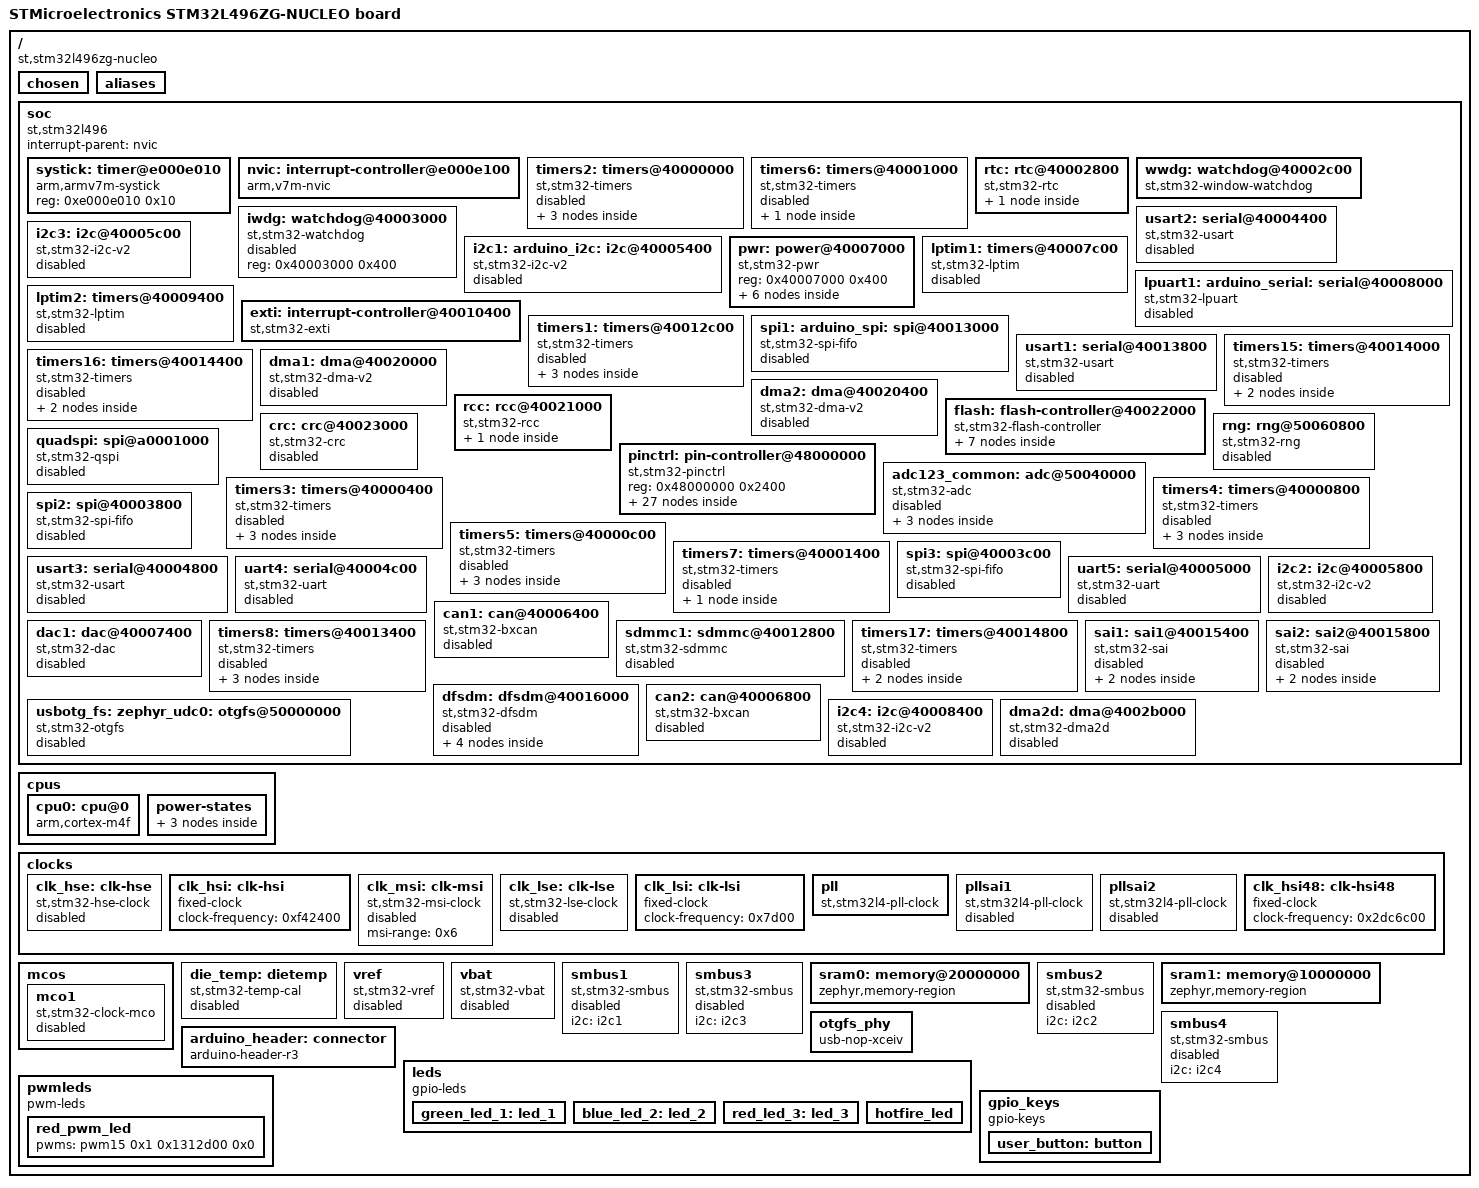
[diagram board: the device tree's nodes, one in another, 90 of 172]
/dts-v1/;

/* node '/' defined in zephyr/dts/common/skeleton.dtsi:9 */
/ {
	#address-cells = < 0x1 >;                              /* in zephyr/dts/common/skeleton.dtsi:10 */
	#size-cells = < 0x1 >;                                 /* in zephyr/dts/common/skeleton.dtsi:11 */
	compatible = "st,stm32l496zg-nucleo";                  /* in zephyr/boards/st/nucleo_l496zg/nucleo_l496zg.dts:14 */
	model = "STMicroelectronics STM32L496ZG-NUCLEO board"; /* in zephyr/boards/st/nucleo_l496zg/nucleo_l496zg.dts:15 */

	/* node '/chosen' defined in zephyr/dts/common/skeleton.dtsi:13 */
	chosen {
		zephyr,crc = &crc;                /* in zephyr/dts/arm/st/l4/stm32l4.dtsi:25 */
		zephyr,entropy = &rng;            /* in zephyr/dts/arm/st/l4/stm32l4.dtsi:26 */
		zephyr,flash-controller = &flash; /* in zephyr/dts/arm/st/l4/stm32l4.dtsi:27 */
		zephyr,console = &lpuart1;        /* in zephyr/boards/st/nucleo_l496zg/nucleo_l496zg.dts:18 */
		zephyr,shell-uart = &lpuart1;     /* in zephyr/boards/st/nucleo_l496zg/nucleo_l496zg.dts:19 */
		zephyr,sram = &sram0;             /* in zephyr/boards/st/nucleo_l496zg/nucleo_l496zg.dts:20 */
		zephyr,flash = &flash0;           /* in zephyr/boards/st/nucleo_l496zg/nucleo_l496zg.dts:21 */
	};

	/* node '/aliases' defined in zephyr/dts/common/skeleton.dtsi:15 */
	aliases {
		led1 = &blue_led_2;      /* in zephyr/boards/st/nucleo_l496zg/nucleo_l496zg.dts:63 */
		led2 = &red_led_3;       /* in zephyr/boards/st/nucleo_l496zg/nucleo_l496zg.dts:64 */
		pwm-led0 = &red_pwm_led; /* in zephyr/boards/st/nucleo_l496zg/nucleo_l496zg.dts:65 */
		sw0 = &user_button;      /* in zephyr/boards/st/nucleo_l496zg/nucleo_l496zg.dts:66 */
		watchdog0 = &wwdg;       /* in zephyr/boards/st/nucleo_l496zg/nucleo_l496zg.dts:67 */
		led0 = &hotfire_led;     /* in ../projects/grp/daq-module/firmware/app.overlay:13 */
	};

	/* node '/soc' defined in zephyr/dts/arm/armv7-m.dtsi:6 */
	soc {
		ranges;                       /* in zephyr/dts/arm/armv7-m.dtsi:8 */
		#address-cells = < 0x1 >;     /* in zephyr/dts/arm/armv7-m.dtsi:9 */
		#size-cells = < 0x1 >;        /* in zephyr/dts/arm/armv7-m.dtsi:10 */
		interrupt-parent = < &nvic >; /* in zephyr/dts/arm/armv7-m.dtsi:11 */
		compatible = "st,stm32l496",
		             "st,stm32l4",
		             "simple-bus";    /* in zephyr/dts/arm/st/l4/stm32l496.dtsi:20 */

		/* node '/soc/timer@e000e010' defined in zephyr/dts/arm/armv7-m.dtsi:13 */
		systick: timer@e000e010 {
			compatible = "arm,armv7m-systick"; /* in zephyr/dts/arm/armv7-m.dtsi:14 */
			reg = < 0xe000e010 0x10 >;         /* in zephyr/dts/arm/armv7-m.dtsi:15 */
		};

		/* node '/soc/interrupt-controller@e000e100' defined in zephyr/dts/arm/armv7-m.dtsi:18 */
		nvic: interrupt-controller@e000e100 {
			compatible = "arm,v7m-nvic";         /* in zephyr/dts/arm/armv7-m.dtsi:19 */
			reg = < 0xe000e100 0xc00 >;          /* in zephyr/dts/arm/armv7-m.dtsi:20 */
			#address-cells = < 0x1 >;            /* in zephyr/dts/arm/armv7-m.dtsi:21 */
			interrupt-controller;                /* in zephyr/dts/arm/armv7-m.dtsi:22 */
			#interrupt-cells = < 0x2 >;          /* in zephyr/dts/arm/armv7-m.dtsi:23 */
			arm,num-irq-priority-bits = < 0x4 >; /* in zephyr/dts/arm/st/l4/stm32l4.dtsi:647 */
			phandle = < 0x1 >;                   /* in zephyr/dts/arm/armv7-m.dtsi:11 */
		};

		/* node '/soc/timers@40000000' defined in zephyr/dts/arm/st/l4/stm32l4.dtsi:123 */
		timers2: timers@40000000 {
			compatible = "st,stm32-timers"; /* in zephyr/dts/arm/st/l4/stm32l4.dtsi:124 */
			reg = < 0x40000000 0x400 >;     /* in zephyr/dts/arm/st/l4/stm32l4.dtsi:125 */
			clocks = < &rcc 0x58 0x1 >,
			         < &rcc 0x9 0xff >;     /* in zephyr/dts/arm/st/l4/stm32l4.dtsi:126 */
			resets = < &rctl 0x700 >;       /* in zephyr/dts/arm/st/l4/stm32l4.dtsi:128 */
			interrupts = < 0x1c 0x0 >;      /* in zephyr/dts/arm/st/l4/stm32l4.dtsi:129 */
			interrupt-names = "global";     /* in zephyr/dts/arm/st/l4/stm32l4.dtsi:130 */
			st,prescaler = < 0x0 >;         /* in zephyr/dts/arm/st/l4/stm32l4.dtsi:131 */
			status = "disabled";            /* in ../projects/grp/daq-module/firmware/app.overlay:30 */

			/* node '/soc/timers@40000000/pwm' defined in zephyr/dts/arm/st/l4/stm32l4.dtsi:134 */
			pwm2: pwm {
				compatible = "st,stm32-pwm";   /* in zephyr/dts/arm/st/l4/stm32l4.dtsi:135 */
				#pwm-cells = < 0x3 >;          /* in zephyr/dts/arm/st/l4/stm32l4.dtsi:136 */
				pinctrl-0 = < &tim2_ch1_pa0 >; /* in zephyr/boards/st/nucleo_l496zg/nucleo_l496zg.dts:145 */
				pinctrl-names = "default";     /* in zephyr/boards/st/nucleo_l496zg/nucleo_l496zg.dts:146 */
				status = "okay";               /* in zephyr/boards/st/nucleo_l496zg/nucleo_l496zg.dts:147 */
			};

			/* node '/soc/timers@40000000/counter' defined in zephyr/dts/arm/st/l4/stm32l4.dtsi:140 */
			counter {
				compatible = "st,stm32-counter"; /* in zephyr/dts/arm/st/l4/stm32l4.dtsi:141 */
				status = "disabled";             /* in zephyr/dts/arm/st/l4/stm32l4.dtsi:142 */
			};

			/* node '/soc/timers@40000000/qdec' defined in zephyr/dts/arm/st/l4/stm32l4.dtsi:145 */
			qdec {
				compatible = "st,stm32-qdec";    /* in zephyr/dts/arm/st/l4/stm32l4.dtsi:146 */
				st,input-filter-level = < 0x0 >; /* in zephyr/dts/arm/st/l4/stm32l4.dtsi:147 */
				status = "disabled";             /* in zephyr/dts/arm/st/l4/stm32l4.dtsi:148 */
			};
		};

		/* node '/soc/timers@40001000' defined in zephyr/dts/arm/st/l4/stm32l4.dtsi:152 */
		timers6: timers@40001000 {
			compatible = "st,stm32-timers"; /* in zephyr/dts/arm/st/l4/stm32l4.dtsi:153 */
			reg = < 0x40001000 0x400 >;     /* in zephyr/dts/arm/st/l4/stm32l4.dtsi:154 */
			clocks = < &rcc 0x58 0x10 >,
			         < &rcc 0x9 0xff >;     /* in zephyr/dts/arm/st/l4/stm32l4.dtsi:155 */
			resets = < &rctl 0x704 >;       /* in zephyr/dts/arm/st/l4/stm32l4.dtsi:157 */
			interrupts = < 0x36 0x0 >;      /* in zephyr/dts/arm/st/l4/stm32l4.dtsi:158 */
			interrupt-names = "global";     /* in zephyr/dts/arm/st/l4/stm32l4.dtsi:159 */
			st,prescaler = < 0x0 >;         /* in zephyr/dts/arm/st/l4/stm32l4.dtsi:160 */
			status = "disabled";            /* in zephyr/dts/arm/st/l4/stm32l4.dtsi:161 */

			/* node '/soc/timers@40001000/counter' defined in zephyr/dts/arm/st/l4/stm32l4.dtsi:163 */
			counter {
				compatible = "st,stm32-counter"; /* in zephyr/dts/arm/st/l4/stm32l4.dtsi:164 */
				status = "disabled";             /* in zephyr/dts/arm/st/l4/stm32l4.dtsi:165 */
			};
		};

		/* node '/soc/rtc@40002800' defined in zephyr/dts/arm/st/l4/stm32l4.dtsi:169 */
		rtc: rtc@40002800 {
			compatible = "st,stm32-rtc";       /* in zephyr/dts/arm/st/l4/stm32l4.dtsi:170 */
			reg = < 0x40002800 0x400 >;        /* in zephyr/dts/arm/st/l4/stm32l4.dtsi:171 */
			interrupts = < 0x29 0x0 >;         /* in zephyr/dts/arm/st/l4/stm32l4.dtsi:172 */
			prescaler = < 0x8000 >;            /* in zephyr/dts/arm/st/l4/stm32l4.dtsi:174 */
			alarms-count = < 0x2 >;            /* in zephyr/dts/arm/st/l4/stm32l4.dtsi:175 */
			alrm-exti-line = < 0x12 >;         /* in zephyr/dts/arm/st/l4/stm32l4.dtsi:176 */
			clocks = < &rcc 0x58 0x10000000 >,
			         < &rcc 0x3 0x2280090 >;   /* in zephyr/boards/st/nucleo_l496zg/nucleo_l496zg.dts:179 */
			status = "okay";                   /* in zephyr/boards/st/nucleo_l496zg/nucleo_l496zg.dts:181 */

			/* node '/soc/rtc@40002800/backup_regs' defined in zephyr/dts/arm/st/l4/stm32l471.dtsi:126 */
			bbram: backup_regs {
				compatible = "st,stm32-bbram"; /* in zephyr/dts/arm/st/l4/stm32l471.dtsi:127 */
				st,backup-regs = < 0x20 >;     /* in zephyr/dts/arm/st/l4/stm32l471.dtsi:128 */
				status = "disabled";           /* in zephyr/dts/arm/st/l4/stm32l471.dtsi:129 */
			};
		};

		/* node '/soc/watchdog@40002c00' defined in zephyr/dts/arm/st/l4/stm32l4.dtsi:180 */
		wwdg: watchdog@40002c00 {
			compatible = "st,stm32-window-watchdog"; /* in zephyr/dts/arm/st/l4/stm32l4.dtsi:181 */
			reg = < 0x40002c00 0x400 >;              /* in zephyr/dts/arm/st/l4/stm32l4.dtsi:182 */
			clocks = < &rcc 0x58 0x800 >;            /* in zephyr/dts/arm/st/l4/stm32l4.dtsi:183 */
			interrupts = < 0x0 0x0 >;                /* in zephyr/dts/arm/st/l4/stm32l4.dtsi:184 */
			status = "okay";                         /* in zephyr/boards/st/nucleo_l496zg/nucleo_l496zg.dts:185 */
		};

		/* node '/soc/watchdog@40003000' defined in zephyr/dts/arm/st/l4/stm32l4.dtsi:188 */
		iwdg: watchdog@40003000 {
			compatible = "st,stm32-watchdog"; /* in zephyr/dts/arm/st/l4/stm32l4.dtsi:189 */
			reg = < 0x40003000 0x400 >;       /* in zephyr/dts/arm/st/l4/stm32l4.dtsi:190 */
			status = "disabled";              /* in zephyr/dts/arm/st/l4/stm32l4.dtsi:191 */
		};

		/* node '/soc/serial@40004400' defined in zephyr/dts/arm/st/l4/stm32l4.dtsi:194 */
		usart2: serial@40004400 {
			compatible = "st,stm32-usart",
			             "st,stm32-uart";                  /* in zephyr/dts/arm/st/l4/stm32l4.dtsi:195 */
			reg = < 0x40004400 0x400 >;                    /* in zephyr/dts/arm/st/l4/stm32l4.dtsi:196 */
			clocks = < &rcc 0x58 0x20000 >;                /* in zephyr/dts/arm/st/l4/stm32l4.dtsi:197 */
			resets = < &rctl 0x711 >;                      /* in zephyr/dts/arm/st/l4/stm32l4.dtsi:198 */
			interrupts = < 0x26 0x0 >;                     /* in zephyr/dts/arm/st/l4/stm32l4.dtsi:199 */
			pinctrl-0 = < &usart2_tx_pd5 &usart2_rx_pd6 >; /* in zephyr/boards/st/nucleo_l496zg/nucleo_l496zg.dts:102 */
			pinctrl-names = "default";                     /* in zephyr/boards/st/nucleo_l496zg/nucleo_l496zg.dts:103 */
			current-speed = < 0x1c200 >;                   /* in zephyr/boards/st/nucleo_l496zg/nucleo_l496zg.dts:104 */
			status = "disabled";                           /* in ../projects/grp/daq-module/firmware/app.overlay:24 */
		};

		/* node '/soc/i2c@40005400' defined in zephyr/dts/arm/st/l4/stm32l4.dtsi:203 */
		i2c1: arduino_i2c: i2c@40005400 {
			compatible = "st,stm32-i2c-v2";              /* in zephyr/dts/arm/st/l4/stm32l4.dtsi:204 */
			reg = < 0x40005400 0x400 >;                  /* in zephyr/dts/arm/st/l4/stm32l4.dtsi:205 */
			#address-cells = < 0x1 >;                    /* in zephyr/dts/arm/st/l4/stm32l4.dtsi:207 */
			#size-cells = < 0x0 >;                       /* in zephyr/dts/arm/st/l4/stm32l4.dtsi:208 */
			clocks = < &rcc 0x58 0x200000 >;             /* in zephyr/dts/arm/st/l4/stm32l4.dtsi:209 */
			interrupts = < 0x1f 0x0 >,
			             < 0x20 0x0 >;                   /* in zephyr/dts/arm/st/l4/stm32l4.dtsi:210 */
			interrupt-names = "event",
			                  "error";                   /* in zephyr/dts/arm/st/l4/stm32l4.dtsi:211 */
			pinctrl-0 = < &i2c1_scl_pb8 &i2c1_sda_pb9 >; /* in zephyr/boards/st/nucleo_l496zg/nucleo_l496zg.dts:163 */
			pinctrl-names = "default";                   /* in zephyr/boards/st/nucleo_l496zg/nucleo_l496zg.dts:164 */
			scl-gpios = < &gpiob 0x8 0x0 >;              /* in zephyr/boards/st/nucleo_l496zg/nucleo_l496zg.dts:165 */
			sda-gpios = < &gpiob 0x9 0x0 >;              /* in zephyr/boards/st/nucleo_l496zg/nucleo_l496zg.dts:166 */
			clock-frequency = < 0x61a80 >;               /* in zephyr/boards/st/nucleo_l496zg/nucleo_l496zg.dts:167 */
			status = "disabled";                         /* in ../projects/grp/daq-module/firmware/app.overlay:28 */
			phandle = < 0x23 >;                          /* in zephyr/dts/arm/st/l4/stm32l4.dtsi:628 */
		};

		/* node '/soc/i2c@40005c00' defined in zephyr/dts/arm/st/l4/stm32l4.dtsi:215 */
		i2c3: i2c@40005c00 {
			compatible = "st,stm32-i2c-v2";  /* in zephyr/dts/arm/st/l4/stm32l4.dtsi:216 */
			reg = < 0x40005c00 0x400 >;      /* in zephyr/dts/arm/st/l4/stm32l4.dtsi:217 */
			clock-frequency = < 0x186a0 >;   /* in zephyr/dts/arm/st/l4/stm32l4.dtsi:218 */
			#address-cells = < 0x1 >;        /* in zephyr/dts/arm/st/l4/stm32l4.dtsi:219 */
			#size-cells = < 0x0 >;           /* in zephyr/dts/arm/st/l4/stm32l4.dtsi:220 */
			clocks = < &rcc 0x58 0x800000 >; /* in zephyr/dts/arm/st/l4/stm32l4.dtsi:221 */
			interrupts = < 0x48 0x0 >,
			             < 0x49 0x0 >;       /* in zephyr/dts/arm/st/l4/stm32l4.dtsi:222 */
			interrupt-names = "event",
			                  "error";       /* in zephyr/dts/arm/st/l4/stm32l4.dtsi:223 */
			status = "disabled";             /* in zephyr/dts/arm/st/l4/stm32l4.dtsi:224 */
			phandle = < 0x24 >;              /* in zephyr/dts/arm/st/l4/stm32l4.dtsi:636 */
		};

		/* node '/soc/power@40007000' defined in zephyr/dts/arm/st/l4/stm32l4.dtsi:227 */
		pwr: power@40007000 {
			compatible = "st,stm32-pwr"; /* in zephyr/dts/arm/st/l4/stm32l4.dtsi:228 */
			reg = < 0x40007000 0x400 >;  /* in zephyr/dts/arm/st/l4/stm32l4.dtsi:229 */

			/* node '/soc/power@40007000/wakeup-controller' defined in zephyr/dts/arm/st/l4/stm32l4.dtsi:231 */
			wakeup-controller {
				compatible = "st,stm32-pwr-wkupctrl"; /* in zephyr/dts/arm/st/l4/stm32l4.dtsi:232 */
				#address-cells = < 0x1 >;             /* in zephyr/dts/arm/st/l4/stm32l4.dtsi:233 */
				#size-cells = < 0x0 >;                /* in zephyr/dts/arm/st/l4/stm32l4.dtsi:234 */
				st,max-wkup-line-idx = < 0x5 >;       /* in zephyr/dts/arm/st/l4/stm32l4.dtsi:236 */
				st,has-pwr-full-pupd;                 /* in zephyr/dts/arm/st/l4/stm32l4.dtsi:237 */
				status = "disabled";                  /* in zephyr/dts/arm/st/l4/stm32l4.dtsi:238 */

				/* node '/soc/power@40007000/wakeup-controller/wkup@1' defined in zephyr/dts/arm/st/l4/stm32l4.dtsi:240 */
				wkup@1 {
					reg = < 0x1 >; /* in zephyr/dts/arm/st/l4/stm32l4.dtsi:241 */
				};

				/* node '/soc/power@40007000/wakeup-controller/wkup@2' defined in zephyr/dts/arm/st/l4/stm32l4.dtsi:244 */
				wkup@2 {
					reg = < 0x2 >; /* in zephyr/dts/arm/st/l4/stm32l4.dtsi:245 */
				};

				/* node '/soc/power@40007000/wakeup-controller/wkup@3' defined in zephyr/dts/arm/st/l4/stm32l4.dtsi:248 */
				wkup@3 {
					reg = < 0x3 >; /* in zephyr/dts/arm/st/l4/stm32l4.dtsi:249 */
				};

				/* node '/soc/power@40007000/wakeup-controller/wkup@4' defined in zephyr/dts/arm/st/l4/stm32l4.dtsi:252 */
				wkup@4 {
					reg = < 0x4 >; /* in zephyr/dts/arm/st/l4/stm32l4.dtsi:253 */
				};

				/* node '/soc/power@40007000/wakeup-controller/wkup@5' defined in zephyr/dts/arm/st/l4/stm32l4.dtsi:256 */
				wkup@5 {
					reg = < 0x5 >; /* in zephyr/dts/arm/st/l4/stm32l4.dtsi:257 */
				};
			};
		};

		/* node '/soc/timers@40007c00' defined in zephyr/dts/arm/st/l4/stm32l4.dtsi:262 */
		lptim1: timers@40007c00 {
			compatible = "st,stm32-lptim";     /* in zephyr/dts/arm/st/l4/stm32l4.dtsi:263 */
			reg = < 0x40007c00 0x400 >;        /* in zephyr/dts/arm/st/l4/stm32l4.dtsi:264 */
			clocks = < &rcc 0x58 0x80000000 >; /* in zephyr/dts/arm/st/l4/stm32l4.dtsi:265 */
			resets = < &rctl 0x71f >;          /* in zephyr/dts/arm/st/l4/stm32l4.dtsi:266 */
			#address-cells = < 0x1 >;          /* in zephyr/dts/arm/st/l4/stm32l4.dtsi:267 */
			#size-cells = < 0x0 >;             /* in zephyr/dts/arm/st/l4/stm32l4.dtsi:268 */
			interrupts = < 0x41 0x0 >;         /* in zephyr/dts/arm/st/l4/stm32l4.dtsi:269 */
			interrupt-names = "wakeup";        /* in zephyr/dts/arm/st/l4/stm32l4.dtsi:270 */
			status = "disabled";               /* in zephyr/dts/arm/st/l4/stm32l4.dtsi:271 */
		};

		/* node '/soc/serial@40008000' defined in zephyr/dts/arm/st/l4/stm32l4.dtsi:274 */
		lpuart1: arduino_serial: serial@40008000 {
			compatible = "st,stm32-lpuart",
			             "st,stm32-uart";                    /* in zephyr/dts/arm/st/l4/stm32l4.dtsi:275 */
			reg = < 0x40008000 0x400 >;                      /* in zephyr/dts/arm/st/l4/stm32l4.dtsi:276 */
			clocks = < &rcc 0x5c 0x1 >;                      /* in zephyr/dts/arm/st/l4/stm32l4.dtsi:277 */
			resets = < &rctl 0x780 >;                        /* in zephyr/dts/arm/st/l4/stm32l4.dtsi:278 */
			interrupts = < 0x46 0x0 >;                       /* in zephyr/dts/arm/st/l4/stm32l4.dtsi:279 */
			pinctrl-0 = < &lpuart1_tx_pg7 &lpuart1_rx_pg8 >; /* in zephyr/boards/st/nucleo_l496zg/nucleo_l496zg.dts:116 */
			pinctrl-names = "default";                       /* in zephyr/boards/st/nucleo_l496zg/nucleo_l496zg.dts:117 */
			current-speed = < 0x1c200 >;                     /* in zephyr/boards/st/nucleo_l496zg/nucleo_l496zg.dts:118 */
			status = "disabled";                             /* in ../projects/grp/daq-module/firmware/app.overlay:26 */
		};

		/* node '/soc/timers@40009400' defined in zephyr/dts/arm/st/l4/stm32l4.dtsi:283 */
		lptim2: timers@40009400 {
			compatible = "st,stm32-lptim"; /* in zephyr/dts/arm/st/l4/stm32l4.dtsi:284 */
			reg = < 0x40009400 0x400 >;    /* in zephyr/dts/arm/st/l4/stm32l4.dtsi:285 */
			#address-cells = < 0x1 >;      /* in zephyr/dts/arm/st/l4/stm32l4.dtsi:286 */
			#size-cells = < 0x0 >;         /* in zephyr/dts/arm/st/l4/stm32l4.dtsi:287 */
			clocks = < &rcc 0x5c 0x20 >;   /* in zephyr/dts/arm/st/l4/stm32l4.dtsi:288 */
			resets = < &rctl 0x785 >;      /* in zephyr/dts/arm/st/l4/stm32l4.dtsi:289 */
			interrupts = < 0x42 0x0 >;     /* in zephyr/dts/arm/st/l4/stm32l4.dtsi:290 */
			interrupt-names = "wakeup";    /* in zephyr/dts/arm/st/l4/stm32l4.dtsi:291 */
			status = "disabled";           /* in zephyr/dts/arm/st/l4/stm32l4.dtsi:292 */
		};

		/* node '/soc/interrupt-controller@40010400' defined in zephyr/dts/arm/st/l4/stm32l4.dtsi:295 */
		exti: interrupt-controller@40010400 {
			compatible = "st,stm32-exti";  /* in zephyr/dts/arm/st/l4/stm32l4.dtsi:296 */
			reg = < 0x40010400 0x400 >;    /* in zephyr/dts/arm/st/l4/stm32l4.dtsi:297 */
			interrupt-controller;          /* in zephyr/dts/arm/st/l4/stm32l4.dtsi:298 */
			#interrupt-cells = < 0x1 >;    /* in zephyr/dts/arm/st/l4/stm32l4.dtsi:299 */
			#address-cells = < 0x0 >;      /* in zephyr/dts/arm/st/l4/stm32l4.dtsi:300 */
			clocks = < &rcc 0x60 0x1 >;    /* in zephyr/dts/arm/st/l4/stm32l4.dtsi:301 */
			num-lines = < 0x40 >;          /* in zephyr/dts/arm/st/l4/stm32l4.dtsi:302 */
			interrupts = < 0x6 0x0 >,
			             < 0x7 0x0 >,
			             < 0x8 0x0 >,
			             < 0x9 0x0 >,
			             < 0xa 0x0 >,
			             < 0x17 0x0 >,
			             < 0x28 0x0 >;     /* in zephyr/dts/arm/st/l4/stm32l4.dtsi:303 */
			interrupt-names = "line0",
			                  "line1",
			                  "line2",
			                  "line3",
			                  "line4",
			                  "line5-9",
			                  "line10-15"; /* in zephyr/dts/arm/st/l4/stm32l4.dtsi:305 */
			line-ranges = < 0x0 0x1 >,
			              < 0x1 0x1 >,
			              < 0x2 0x1 >,
			              < 0x3 0x1 >,
			              < 0x4 0x1 >,
			              < 0x5 0x5 >,
			              < 0xa 0x6 >;     /* in zephyr/dts/arm/st/l4/stm32l4.dtsi:307 */
		};

		/* node '/soc/timers@40012c00' defined in zephyr/dts/arm/st/l4/stm32l4.dtsi:311 */
		timers1: timers@40012c00 {
			compatible = "st,stm32-timers"; /* in zephyr/dts/arm/st/l4/stm32l4.dtsi:312 */
			reg = < 0x40012c00 0x400 >;     /* in zephyr/dts/arm/st/l4/stm32l4.dtsi:313 */
			clocks = < &rcc 0x60 0x800 >,
			         < &rcc 0xa 0xff >;     /* in zephyr/dts/arm/st/l4/stm32l4.dtsi:314 */
			resets = < &rctl 0x80b >;       /* in zephyr/dts/arm/st/l4/stm32l4.dtsi:316 */
			interrupts = < 0x18 0x0 >,
			             < 0x19 0x0 >,
			             < 0x1a 0x0 >,
			             < 0x1b 0x0 >;      /* in zephyr/dts/arm/st/l4/stm32l4.dtsi:317 */
			interrupt-names = "brk",
			                  "up",
			                  "trgcom",
			                  "cc";         /* in zephyr/dts/arm/st/l4/stm32l4.dtsi:318 */
			st,prescaler = < 0x2710 >;      /* in zephyr/boards/st/nucleo_l496zg/nucleo_l496zg.dts:129 */
			status = "disabled";            /* in ../projects/grp/daq-module/firmware/app.overlay:29 */

			/* node '/soc/timers@40012c00/pwm' defined in zephyr/dts/arm/st/l4/stm32l4.dtsi:322 */
			pwm1: pwm {
				compatible = "st,stm32-pwm";                                 /* in zephyr/dts/arm/st/l4/stm32l4.dtsi:323 */
				#pwm-cells = < 0x3 >;                                        /* in zephyr/dts/arm/st/l4/stm32l4.dtsi:324 */
				pinctrl-0 = < &tim1_ch1_pe9 &tim1_ch2_pe11 &tim1_ch3_pe13 >; /* in zephyr/boards/st/nucleo_l496zg/nucleo_l496zg.dts:133 */
				pinctrl-names = "default";                                   /* in zephyr/boards/st/nucleo_l496zg/nucleo_l496zg.dts:136 */
				status = "okay";                                             /* in zephyr/boards/st/nucleo_l496zg/nucleo_l496zg.dts:137 */
			};

			/* node '/soc/timers@40012c00/counter' defined in zephyr/dts/arm/st/l4/stm32l4.dtsi:328 */
			counter {
				compatible = "st,stm32-counter"; /* in zephyr/dts/arm/st/l4/stm32l4.dtsi:329 */
				status = "disabled";             /* in zephyr/dts/arm/st/l4/stm32l4.dtsi:330 */
			};

			/* node '/soc/timers@40012c00/qdec' defined in zephyr/dts/arm/st/l4/stm32l4.dtsi:333 */
			qdec {
				compatible = "st,stm32-qdec";    /* in zephyr/dts/arm/st/l4/stm32l4.dtsi:334 */
				st,input-filter-level = < 0x0 >; /* in zephyr/dts/arm/st/l4/stm32l4.dtsi:335 */
				status = "disabled";             /* in zephyr/dts/arm/st/l4/stm32l4.dtsi:336 */
			};
		};

		/* node '/soc/spi@40013000' defined in zephyr/dts/arm/st/l4/stm32l4.dtsi:340 */
		spi1: arduino_spi: spi@40013000 {
			compatible = "st,stm32-spi-fifo",
			             "st,stm32-spi";                                 /* in zephyr/dts/arm/st/l4/stm32l4.dtsi:341 */
			reg = < 0x40013000 0x400 >;                                  /* in zephyr/dts/arm/st/l4/stm32l4.dtsi:342 */
			#address-cells = < 0x1 >;                                    /* in zephyr/dts/arm/st/l4/stm32l4.dtsi:343 */
			#size-cells = < 0x0 >;                                       /* in zephyr/dts/arm/st/l4/stm32l4.dtsi:344 */
			interrupts = < 0x23 0x0 >;                                   /* in zephyr/dts/arm/st/l4/stm32l4.dtsi:345 */
			clocks = < &rcc 0x60 0x1000 >;                               /* in zephyr/dts/arm/st/l4/stm32l4.dtsi:346 */
			st,spi-data-width = "full-4-to-16-bit";                      /* in zephyr/dts/arm/st/l4/stm32l4.dtsi:347 */
			pinctrl-0 = < &spi1_sck_pa5 &spi1_miso_pa6 &spi1_mosi_pa7 >; /* in zephyr/boards/st/nucleo_l496zg/nucleo_l496zg.dts:172 */
			pinctrl-names = "default";                                   /* in zephyr/boards/st/nucleo_l496zg/nucleo_l496zg.dts:173 */
			cs-gpios = < &gpiod 0xe 0x11 >;                              /* in zephyr/boards/st/nucleo_l496zg/nucleo_l496zg.dts:174 */
			status = "disabled";                                         /* in ../projects/grp/daq-module/firmware/app.overlay:27 */
		};

		/* node '/soc/serial@40013800' defined in zephyr/dts/arm/st/l4/stm32l4.dtsi:351 */
		usart1: serial@40013800 {
			compatible = "st,stm32-usart",
			             "st,stm32-uart";  /* in zephyr/dts/arm/st/l4/stm32l4.dtsi:352 */
			reg = < 0x40013800 0x400 >;    /* in zephyr/dts/arm/st/l4/stm32l4.dtsi:353 */
			clocks = < &rcc 0x60 0x4000 >; /* in zephyr/dts/arm/st/l4/stm32l4.dtsi:354 */
			resets = < &rctl 0x80e >;      /* in zephyr/dts/arm/st/l4/stm32l4.dtsi:355 */
			interrupts = < 0x25 0x0 >;     /* in zephyr/dts/arm/st/l4/stm32l4.dtsi:356 */
			status = "disabled";           /* in zephyr/dts/arm/st/l4/stm32l4.dtsi:357 */
		};

		/* node '/soc/timers@40014000' defined in zephyr/dts/arm/st/l4/stm32l4.dtsi:360 */
		timers15: timers@40014000 {
			compatible = "st,stm32-timers"; /* in zephyr/dts/arm/st/l4/stm32l4.dtsi:361 */
			reg = < 0x40014000 0x400 >;     /* in zephyr/dts/arm/st/l4/stm32l4.dtsi:362 */
			clocks = < &rcc 0x60 0x10000 >,
			         < &rcc 0xa 0xff >;     /* in zephyr/dts/arm/st/l4/stm32l4.dtsi:363 */
			resets = < &rctl 0x810 >;       /* in zephyr/dts/arm/st/l4/stm32l4.dtsi:365 */
			interrupts = < 0x18 0x0 >;      /* in zephyr/dts/arm/st/l4/stm32l4.dtsi:366 */
			interrupt-names = "global";     /* in zephyr/dts/arm/st/l4/stm32l4.dtsi:367 */
			st,prescaler = < 0x2710 >;      /* in zephyr/boards/st/nucleo_l496zg/nucleo_l496zg.dts:152 */
			status = "disabled";            /* in ../projects/grp/daq-module/firmware/app.overlay:31 */

			/* node '/soc/timers@40014000/pwm' defined in zephyr/dts/arm/st/l4/stm32l4.dtsi:371 */
			pwm15: pwm {
				compatible = "st,stm32-pwm";     /* in zephyr/dts/arm/st/l4/stm32l4.dtsi:372 */
				#pwm-cells = < 0x3 >;            /* in zephyr/dts/arm/st/l4/stm32l4.dtsi:373 */
				pinctrl-0 = < &tim15_ch1_pb14 >; /* in zephyr/boards/st/nucleo_l496zg/nucleo_l496zg.dts:156 */
				pinctrl-names = "default";       /* in zephyr/boards/st/nucleo_l496zg/nucleo_l496zg.dts:157 */
				status = "okay";                 /* in zephyr/boards/st/nucleo_l496zg/nucleo_l496zg.dts:158 */
				phandle = < 0x2b >;              /* in zephyr/boards/st/nucleo_l496zg/nucleo_l496zg.dts:47 */
			};

			/* node '/soc/timers@40014000/counter' defined in zephyr/dts/arm/st/l4/stm32l4.dtsi:377 */
			counter {
				compatible = "st,stm32-counter"; /* in zephyr/dts/arm/st/l4/stm32l4.dtsi:378 */
				status = "disabled";             /* in zephyr/dts/arm/st/l4/stm32l4.dtsi:379 */
			};
		};

		/* node '/soc/timers@40014400' defined in zephyr/dts/arm/st/l4/stm32l4.dtsi:383 */
		timers16: timers@40014400 {
			compatible = "st,stm32-timers"; /* in zephyr/dts/arm/st/l4/stm32l4.dtsi:384 */
			reg = < 0x40014400 0x400 >;     /* in zephyr/dts/arm/st/l4/stm32l4.dtsi:385 */
			clocks = < &rcc 0x60 0x20000 >,
			         < &rcc 0xa 0xff >;     /* in zephyr/dts/arm/st/l4/stm32l4.dtsi:386 */
			resets = < &rctl 0x811 >;       /* in zephyr/dts/arm/st/l4/stm32l4.dtsi:388 */
			interrupts = < 0x19 0x0 >;      /* in zephyr/dts/arm/st/l4/stm32l4.dtsi:389 */
			interrupt-names = "global";     /* in zephyr/dts/arm/st/l4/stm32l4.dtsi:390 */
			st,prescaler = < 0x0 >;         /* in zephyr/dts/arm/st/l4/stm32l4.dtsi:391 */
			status = "disabled";            /* in zephyr/dts/arm/st/l4/stm32l4.dtsi:392 */

			/* node '/soc/timers@40014400/pwm' defined in zephyr/dts/arm/st/l4/stm32l4.dtsi:394 */
			pwm {
				compatible = "st,stm32-pwm"; /* in zephyr/dts/arm/st/l4/stm32l4.dtsi:395 */
				#pwm-cells = < 0x3 >;        /* in zephyr/dts/arm/st/l4/stm32l4.dtsi:396 */
				status = "disabled";         /* in zephyr/dts/arm/st/l4/stm32l4.dtsi:397 */
			};

			/* node '/soc/timers@40014400/counter' defined in zephyr/dts/arm/st/l4/stm32l4.dtsi:400 */
			counter {
				compatible = "st,stm32-counter"; /* in zephyr/dts/arm/st/l4/stm32l4.dtsi:401 */
				status = "disabled";             /* in zephyr/dts/arm/st/l4/stm32l4.dtsi:402 */
			};
		};

		/* node '/soc/dma@40020000' defined in zephyr/dts/arm/st/l4/stm32l4.dtsi:406 */
		dma1: dma@40020000 {
			compatible = "st,stm32-dma-v2"; /* in zephyr/dts/arm/st/l4/stm32l4.dtsi:407 */
			reg = < 0x40020000 0x400 >;     /* in zephyr/dts/arm/st/l4/stm32l4.dtsi:408 */
			#dma-cells = < 0x3 >;           /* in zephyr/dts/arm/st/l4/stm32l4.dtsi:409 */
			interrupts = < 0xb 0x0 >,
			             < 0xc 0x0 >,
			             < 0xd 0x0 >,
			             < 0xe 0x0 >,
			             < 0xf 0x0 >,
			             < 0x10 0x0 >,
			             < 0x11 0x0 >;      /* in zephyr/dts/arm/st/l4/stm32l4.dtsi:410 */
			clocks = < &rcc 0x48 0x1 >;     /* in zephyr/dts/arm/st/l4/stm32l4.dtsi:411 */
			dma-requests = < 0x7 >;         /* in zephyr/dts/arm/st/l4/stm32l4.dtsi:412 */
			status = "disabled";            /* in zephyr/dts/arm/st/l4/stm32l4.dtsi:413 */
		};

		/* node '/soc/dma@40020400' defined in zephyr/dts/arm/st/l4/stm32l4.dtsi:416 */
		dma2: dma@40020400 {
			compatible = "st,stm32-dma-v2"; /* in zephyr/dts/arm/st/l4/stm32l4.dtsi:417 */
			reg = < 0x40020400 0x400 >;     /* in zephyr/dts/arm/st/l4/stm32l4.dtsi:418 */
			#dma-cells = < 0x3 >;           /* in zephyr/dts/arm/st/l4/stm32l4.dtsi:419 */
			interrupts = < 0x38 0x0 >,
			             < 0x39 0x0 >,
			             < 0x3a 0x0 >,
			             < 0x3b 0x0 >,
			             < 0x3c 0x0 >,
			             < 0x44 0x0 >,
			             < 0x45 0x0 >;      /* in zephyr/dts/arm/st/l4/stm32l4.dtsi:420 */
			clocks = < &rcc 0x48 0x2 >;     /* in zephyr/dts/arm/st/l4/stm32l4.dtsi:421 */
			dma-requests = < 0x7 >;         /* in zephyr/dts/arm/st/l4/stm32l4.dtsi:422 */
			status = "disabled";            /* in zephyr/dts/arm/st/l4/stm32l4.dtsi:423 */
			phandle = < 0x17 >;             /* in zephyr/dts/arm/st/l4/stm32l471.dtsi:286 */
		};

		/* node '/soc/rcc@40021000' defined in zephyr/dts/arm/st/l4/stm32l4.dtsi:426 */
		rcc: rcc@40021000 {
			compatible = "st,stm32-rcc";     /* in zephyr/dts/arm/st/l4/stm32l4.dtsi:427 */
			reg = < 0x40021000 0x400 >;      /* in zephyr/dts/arm/st/l4/stm32l4.dtsi:428 */
			#clock-cells = < 0x2 >;          /* in zephyr/dts/arm/st/l4/stm32l4.dtsi:429 */
			clocks = < &pll >;               /* in zephyr/boards/st/nucleo_l496zg/nucleo_l496zg.dts:94 */
			clock-frequency = < 0x4c4b400 >; /* in zephyr/boards/st/nucleo_l496zg/nucleo_l496zg.dts:95 */
			ahb-prescaler = < 0x1 >;         /* in zephyr/boards/st/nucleo_l496zg/nucleo_l496zg.dts:96 */
			apb1-prescaler = < 0x1 >;        /* in zephyr/boards/st/nucleo_l496zg/nucleo_l496zg.dts:97 */
			apb2-prescaler = < 0x1 >;        /* in zephyr/boards/st/nucleo_l496zg/nucleo_l496zg.dts:98 */
			phandle = < 0x2 >;               /* in zephyr/dts/arm/st/l4/stm32l4.dtsi:126 */

			/* node '/soc/rcc@40021000/reset-controller' defined in zephyr/dts/arm/st/l4/stm32l4.dtsi:431 */
			rctl: reset-controller {
				compatible = "st,stm32-rcc-rctl"; /* in zephyr/dts/arm/st/l4/stm32l4.dtsi:432 */
				#reset-cells = < 0x1 >;           /* in zephyr/dts/arm/st/l4/stm32l4.dtsi:433 */
				phandle = < 0x3 >;                /* in zephyr/dts/arm/st/l4/stm32l4.dtsi:128 */
			};
		};

		/* node '/soc/flash-controller@40022000' defined in zephyr/dts/arm/st/l4/stm32l4.dtsi:437 */
		flash: flash-controller@40022000 {
			compatible = "st,stm32-flash-controller",
			             "st,stm32l4-flash-controller"; /* in zephyr/dts/arm/st/l4/stm32l4.dtsi:438 */
			reg = < 0x40022000 0x400 >;                 /* in zephyr/dts/arm/st/l4/stm32l4.dtsi:439 */
			ranges;                                     /* in zephyr/dts/arm/st/l4/stm32l4.dtsi:440 */
			interrupts = < 0x4 0x0 >;                   /* in zephyr/dts/arm/st/l4/stm32l4.dtsi:441 */
			clocks = < &rcc 0x48 0x100 >;               /* in zephyr/dts/arm/st/l4/stm32l4.dtsi:442 */
			#address-cells = < 0x1 >;                   /* in zephyr/dts/arm/st/l4/stm32l4.dtsi:444 */
			#size-cells = < 0x1 >;                      /* in zephyr/dts/arm/st/l4/stm32l4.dtsi:445 */

			/* node '/soc/flash-controller@40022000/flash@8000000' defined in zephyr/dts/arm/st/l4/stm32l4.dtsi:447 */
			flash0: flash@8000000 {
				compatible = "st,stm32-nv-flash",
				             "soc-nv-flash";        /* in zephyr/dts/arm/st/l4/stm32l4.dtsi:448 */
				#address-cells = < 0x1 >;           /* in zephyr/dts/arm/st/l4/stm32l4.dtsi:449 */
				#size-cells = < 0x1 >;              /* in zephyr/dts/arm/st/l4/stm32l4.dtsi:450 */
				write-block-size = < 0x8 >;         /* in zephyr/dts/arm/st/l4/stm32l4.dtsi:451 */
				erase-block-size = < 0x800 >;       /* in zephyr/dts/arm/st/l4/stm32l4.dtsi:452 */
				max-erase-time = < 0x19 >;          /* in zephyr/dts/arm/st/l4/stm32l4.dtsi:454 */
				reg = < 0x8000000 0x80000 >;        /* in ../projects/grp/daq-module/firmware/app.overlay:19 */
				ranges = < 0x0 0x8000000 0x80000 >; /* in ../projects/grp/daq-module/firmware/app.overlay:20 */
			};

			/* node '/soc/flash-controller@40022000/flash@1fff7000' defined in zephyr/dts/arm/st/l4/stm32l4.dtsi:457 */
			st_nvm_user_otp: flash@1fff7000 {
				compatible = "st,stm32-nvm-otp"; /* in zephyr/dts/arm/st/l4/stm32l4.dtsi:458 */
				reg = < 0x1fff7000 0x400 >;      /* in zephyr/dts/arm/st/l4/stm32l4.dtsi:459 */
				status = "disabled";             /* in zephyr/dts/arm/st/l4/stm32l4.dtsi:460 */
			};

			/* node '/soc/flash-controller@40022000/flash@1fff7500' defined in zephyr/dts/arm/st/l4/stm32l4.dtsi:464 */
			flash@1fff7500 {
				compatible = "st,stm32-nvm-otp"; /* in zephyr/dts/arm/st/l4/stm32l4.dtsi:465 */
				reg = < 0x1fff7500 0x300 >;      /* in zephyr/dts/arm/st/l4/stm32l4.dtsi:466 */

				/* node '/soc/flash-controller@40022000/flash@1fff7500/nvmem-layout' defined in zephyr/dts/arm/st/l4/stm32l4.dtsi:468 */
				nvmem-layout {
					compatible = "fixed-layout"; /* in zephyr/dts/arm/st/l4/stm32l4.dtsi:469 */
					#address-cells = < 0x1 >;    /* in zephyr/dts/arm/st/l4/stm32l4.dtsi:470 */
					#size-cells = < 0x1 >;       /* in zephyr/dts/arm/st/l4/stm32l4.dtsi:471 */

					/* node '/soc/flash-controller@40022000/flash@1fff7500/nvmem-layout/ts-cal1@a8' defined in zephyr/dts/arm/st/l4/stm32l4.dtsi:473 */
					ts_cal1_otp: ts-cal1@a8 {
						reg = < 0xa8 0x2 >;          /* in zephyr/dts/arm/st/l4/stm32l4.dtsi:474 */
						#nvmem-cell-cells = < 0x0 >; /* in zephyr/dts/arm/st/l4/stm32l4.dtsi:475 */
						read-only;                   /* in zephyr/dts/arm/st/l4/stm32l4.dtsi:476 */
						phandle = < 0x1f >;          /* in zephyr/dts/arm/st/l4/stm32l4.dtsi:600 */
					};

					/* node '/soc/flash-controller@40022000/flash@1fff7500/nvmem-layout/vrefint@aa' defined in zephyr/dts/arm/st/l4/stm32l4.dtsi:479 */
					vrefint_otp: vrefint@aa {
						reg = < 0xaa 0x2 >;          /* in zephyr/dts/arm/st/l4/stm32l4.dtsi:480 */
						#nvmem-cell-cells = < 0x0 >; /* in zephyr/dts/arm/st/l4/stm32l4.dtsi:481 */
						read-only;                   /* in zephyr/dts/arm/st/l4/stm32l4.dtsi:482 */
						phandle = < 0x22 >;          /* in zephyr/dts/arm/st/l4/stm32l4.dtsi:611 */
					};

					/* node '/soc/flash-controller@40022000/flash@1fff7500/nvmem-layout/ts-cal2@ca' defined in zephyr/dts/arm/st/l4/stm32l4.dtsi:485 */
					ts_cal2_otp: ts-cal2@ca {
						reg = < 0xca 0x2 >;          /* in zephyr/dts/arm/st/l4/stm32l4.dtsi:486 */
						#nvmem-cell-cells = < 0x0 >; /* in zephyr/dts/arm/st/l4/stm32l4.dtsi:487 */
						read-only;                   /* in zephyr/dts/arm/st/l4/stm32l4.dtsi:488 */
						phandle = < 0x20 >;          /* in zephyr/dts/arm/st/l4/stm32l4.dtsi:600 */
					};
				};
			};
		};

		/* node '/soc/crc@40023000' defined in zephyr/dts/arm/st/l4/stm32l4.dtsi:494 */
		crc: crc@40023000 {
			compatible = "st,stm32-crc";   /* in zephyr/dts/arm/st/l4/stm32l4.dtsi:495 */
			reg = < 0x40023000 0x400 >;    /* in zephyr/dts/arm/st/l4/stm32l4.dtsi:496 */
			clocks = < &rcc 0x48 0x1000 >; /* in zephyr/dts/arm/st/l4/stm32l4.dtsi:497 */
			resets = < &rctl 0x50c >;      /* in zephyr/dts/arm/st/l4/stm32l4.dtsi:498 */
			status = "disabled";           /* in zephyr/dts/arm/st/l4/stm32l4.dtsi:499 */
		};

		/* node '/soc/pin-controller@48000000' defined in zephyr/dts/arm/st/l4/stm32l4.dtsi:502 */
		pinctrl: pin-controller@48000000 {
			compatible = "st,stm32-pinctrl"; /* in zephyr/dts/arm/st/l4/stm32l4.dtsi:503 */
			ranges;                          /* in zephyr/dts/arm/st/l4/stm32l4.dtsi:505 */
			#address-cells = < 0x1 >;        /* in zephyr/dts/arm/st/l4/stm32l4.dtsi:506 */
			#size-cells = < 0x1 >;           /* in zephyr/dts/arm/st/l4/stm32l4.dtsi:507 */
			reg = < 0x48000000 0x2400 >;     /* in zephyr/dts/arm/st/l4/stm32l496.dtsi:57 */

			/* node '/soc/pin-controller@48000000/gpio@48000000' defined in zephyr/dts/arm/st/l4/stm32l4.dtsi:509 */
			gpioa: gpio@48000000 {
				compatible = "st,stm32-gpio"; /* in zephyr/dts/arm/st/l4/stm32l4.dtsi:510 */
				reg = < 0x48000000 0x400 >;   /* in zephyr/dts/arm/st/l4/stm32l4.dtsi:511 */
				gpio-controller;              /* in zephyr/dts/arm/st/l4/stm32l4.dtsi:512 */
				#gpio-cells = < 0x2 >;        /* in zephyr/dts/arm/st/l4/stm32l4.dtsi:513 */
				clocks = < &rcc 0x4c 0x1 >;   /* in zephyr/dts/arm/st/l4/stm32l4.dtsi:514 */
				phandle = < 0x27 >;           /* in zephyr/boards/st/nucleo_l496zg/arduino_r3_connector.dtsi:15 */
			};

			/* node '/soc/pin-controller@48000000/gpio@48000400' defined in zephyr/dts/arm/st/l4/stm32l4.dtsi:517 */
			gpiob: gpio@48000400 {
				compatible = "st,stm32-gpio"; /* in zephyr/dts/arm/st/l4/stm32l4.dtsi:518 */
				reg = < 0x48000400 0x400 >;   /* in zephyr/dts/arm/st/l4/stm32l4.dtsi:519 */
				gpio-controller;              /* in zephyr/dts/arm/st/l4/stm32l4.dtsi:520 */
				#gpio-cells = < 0x2 >;        /* in zephyr/dts/arm/st/l4/stm32l4.dtsi:521 */
				clocks = < &rcc 0x4c 0x2 >;   /* in zephyr/dts/arm/st/l4/stm32l4.dtsi:522 */
				phandle = < 0x9 >;            /* in zephyr/boards/st/nucleo_l496zg/nucleo_l496zg.dts:165 */
			};

			/* node '/soc/pin-controller@48000000/gpio@48000800' defined in zephyr/dts/arm/st/l4/stm32l4.dtsi:525 */
			gpioc: gpio@48000800 {
				compatible = "st,stm32-gpio"; /* in zephyr/dts/arm/st/l4/stm32l4.dtsi:526 */
				reg = < 0x48000800 0x400 >;   /* in zephyr/dts/arm/st/l4/stm32l4.dtsi:527 */
				gpio-controller;              /* in zephyr/dts/arm/st/l4/stm32l4.dtsi:528 */
				#gpio-cells = < 0x2 >;        /* in zephyr/dts/arm/st/l4/stm32l4.dtsi:529 */
				clocks = < &rcc 0x4c 0x4 >;   /* in zephyr/dts/arm/st/l4/stm32l4.dtsi:530 */
				phandle = < 0x28 >;           /* in zephyr/boards/st/nucleo_l496zg/arduino_r3_connector.dtsi:15 */
			};

			/* node '/soc/pin-controller@48000000/gpio@48001c00' defined in zephyr/dts/arm/st/l4/stm32l4.dtsi:533 */
			gpioh: gpio@48001c00 {
				compatible = "st,stm32-gpio"; /* in zephyr/dts/arm/st/l4/stm32l4.dtsi:534 */
				reg = < 0x48001c00 0x400 >;   /* in zephyr/dts/arm/st/l4/stm32l4.dtsi:535 */
				gpio-controller;              /* in zephyr/dts/arm/st/l4/stm32l4.dtsi:536 */
				#gpio-cells = < 0x2 >;        /* in zephyr/dts/arm/st/l4/stm32l4.dtsi:537 */
				clocks = < &rcc 0x4c 0x80 >;  /* in zephyr/dts/arm/st/l4/stm32l4.dtsi:538 */
			};

			/* node '/soc/pin-controller@48000000/gpio@48000c00' defined in zephyr/dts/arm/st/l4/stm32l471.dtsi:382 */
			gpiod: gpio@48000c00 {
				compatible = "st,stm32-gpio"; /* in zephyr/dts/arm/st/l4/stm32l471.dtsi:383 */
				reg = < 0x48000c00 0x400 >;   /* in zephyr/dts/arm/st/l4/stm32l471.dtsi:384 */
				gpio-controller;              /* in zephyr/dts/arm/st/l4/stm32l471.dtsi:385 */
				#gpio-cells = < 0x2 >;        /* in zephyr/dts/arm/st/l4/stm32l471.dtsi:386 */
				clocks = < &rcc 0x4c 0x8 >;   /* in zephyr/dts/arm/st/l4/stm32l471.dtsi:387 */
				phandle = < 0x12 >;           /* in zephyr/boards/st/nucleo_l496zg/nucleo_l496zg.dts:174 */
			};

			/* node '/soc/pin-controller@48000000/gpio@48001000' defined in zephyr/dts/arm/st/l4/stm32l471.dtsi:390 */
			gpioe: gpio@48001000 {
				compatible = "st,stm32-gpio"; /* in zephyr/dts/arm/st/l4/stm32l471.dtsi:391 */
				reg = < 0x48001000 0x400 >;   /* in zephyr/dts/arm/st/l4/stm32l471.dtsi:392 */
				gpio-controller;              /* in zephyr/dts/arm/st/l4/stm32l471.dtsi:393 */
				#gpio-cells = < 0x2 >;        /* in zephyr/dts/arm/st/l4/stm32l471.dtsi:394 */
				clocks = < &rcc 0x4c 0x10 >;  /* in zephyr/dts/arm/st/l4/stm32l471.dtsi:395 */
				phandle = < 0x2a >;           /* in zephyr/boards/st/nucleo_l496zg/arduino_r3_connector.dtsi:15 */
			};

			/* node '/soc/pin-controller@48000000/gpio@48001400' defined in zephyr/dts/arm/st/l4/stm32l471.dtsi:398 */
			gpiof: gpio@48001400 {
				compatible = "st,stm32-gpio"; /* in zephyr/dts/arm/st/l4/stm32l471.dtsi:399 */
				reg = < 0x48001400 0x400 >;   /* in zephyr/dts/arm/st/l4/stm32l471.dtsi:400 */
				gpio-controller;              /* in zephyr/dts/arm/st/l4/stm32l471.dtsi:401 */
				#gpio-cells = < 0x2 >;        /* in zephyr/dts/arm/st/l4/stm32l471.dtsi:402 */
				clocks = < &rcc 0x4c 0x20 >;  /* in zephyr/dts/arm/st/l4/stm32l471.dtsi:403 */
				phandle = < 0x29 >;           /* in zephyr/boards/st/nucleo_l496zg/arduino_r3_connector.dtsi:15 */
			};

			/* node '/soc/pin-controller@48000000/gpio@48001800' defined in zephyr/dts/arm/st/l4/stm32l471.dtsi:406 */
			gpiog: gpio@48001800 {
				compatible = "st,stm32-gpio"; /* in zephyr/dts/arm/st/l4/stm32l471.dtsi:407 */
				reg = < 0x48001800 0x400 >;   /* in zephyr/dts/arm/st/l4/stm32l471.dtsi:408 */
				gpio-controller;              /* in zephyr/dts/arm/st/l4/stm32l471.dtsi:409 */
				#gpio-cells = < 0x2 >;        /* in zephyr/dts/arm/st/l4/stm32l471.dtsi:410 */
				clocks = < &rcc 0x4c 0x40 >;  /* in zephyr/dts/arm/st/l4/stm32l471.dtsi:411 */
			};

			/* node '/soc/pin-controller@48000000/gpio@48002000' defined in zephyr/dts/arm/st/l4/stm32l496.dtsi:59 */
			gpioi: gpio@48002000 {
				compatible = "st,stm32-gpio"; /* in zephyr/dts/arm/st/l4/stm32l496.dtsi:60 */
				reg = < 0x48002000 0x400 >;   /* in zephyr/dts/arm/st/l4/stm32l496.dtsi:61 */
				gpio-controller;              /* in zephyr/dts/arm/st/l4/stm32l496.dtsi:62 */
				#gpio-cells = < 0x2 >;        /* in zephyr/dts/arm/st/l4/stm32l496.dtsi:63 */
				ngpios = < 0xc >;             /* in zephyr/dts/arm/st/l4/stm32l496.dtsi:64 */
				clocks = < &rcc 0x4c 0x100 >; /* in zephyr/dts/arm/st/l4/stm32l496.dtsi:65 */
			};

			/* node '/soc/pin-controller@48000000/i2c1_scl_pb8' defined in modules/hal/stm32/dts/st/l4/stm32l496z(e-g)tx-pinctrl.dtsi:1426 */
			i2c1_scl_pb8: i2c1_scl_pb8 {
				pinmux = < 0x304 >; /* in modules/hal/stm32/dts/st/l4/stm32l496z(e-g)tx-pinctrl.dtsi:1427 */
				bias-pull-up;       /* in modules/hal/stm32/dts/st/l4/stm32l496z(e-g)tx-pinctrl.dtsi:1428 */
				drive-open-drain;   /* in modules/hal/stm32/dts/st/l4/stm32l496z(e-g)tx-pinctrl.dtsi:1429 */
				phandle = < 0x7 >;  /* in zephyr/boards/st/nucleo_l496zg/nucleo_l496zg.dts:163 */
			};

			/* node '/soc/pin-controller@48000000/i2c1_sda_pb9' defined in modules/hal/stm32/dts/st/l4/stm32l496z(e-g)tx-pinctrl.dtsi:1511 */
			i2c1_sda_pb9: i2c1_sda_pb9 {
				pinmux = < 0x324 >; /* in modules/hal/stm32/dts/st/l4/stm32l496z(e-g)tx-pinctrl.dtsi:1512 */
				bias-pull-up;       /* in modules/hal/stm32/dts/st/l4/stm32l496z(e-g)tx-pinctrl.dtsi:1513 */
				drive-open-drain;   /* in modules/hal/stm32/dts/st/l4/stm32l496z(e-g)tx-pinctrl.dtsi:1514 */
				phandle = < 0x8 >;  /* in zephyr/boards/st/nucleo_l496zg/nucleo_l496zg.dts:163 */
			};

			/* node '/soc/pin-controller@48000000/spi1_miso_pa6' defined in modules/hal/stm32/dts/st/l4/stm32l496z(e-g)tx-pinctrl.dtsi:2503 */
			spi1_miso_pa6: spi1_miso_pa6 {
				pinmux = < 0xc5 >;             /* in modules/hal/stm32/dts/st/l4/stm32l496z(e-g)tx-pinctrl.dtsi:2504 */
				bias-pull-down;                /* in modules/hal/stm32/dts/st/l4/stm32l496z(e-g)tx-pinctrl.dtsi:2505 */
				slew-rate = "very-high-speed"; /* in modules/hal/stm32/dts/st/l4/stm32l496z(e-g)tx-pinctrl.dtsi:2506 */
				phandle = < 0x10 >;            /* in zephyr/boards/st/nucleo_l496zg/nucleo_l496zg.dts:172 */
			};

			/* node '/soc/pin-controller@48000000/spi1_mosi_pa7' defined in modules/hal/stm32/dts/st/l4/stm32l496z(e-g)tx-pinctrl.dtsi:2570 */
			spi1_mosi_pa7: spi1_mosi_pa7 {
				pinmux = < 0xe5 >;             /* in modules/hal/stm32/dts/st/l4/stm32l496z(e-g)tx-pinctrl.dtsi:2571 */
				bias-pull-down;                /* in modules/hal/stm32/dts/st/l4/stm32l496z(e-g)tx-pinctrl.dtsi:2572 */
				slew-rate = "very-high-speed"; /* in modules/hal/stm32/dts/st/l4/stm32l496z(e-g)tx-pinctrl.dtsi:2573 */
				phandle = < 0x11 >;            /* in zephyr/boards/st/nucleo_l496zg/nucleo_l496zg.dts:172 */
			};

			/* node '/soc/pin-controller@48000000/spi1_sck_pa5' defined in modules/hal/stm32/dts/st/l4/stm32l496z(e-g)tx-pinctrl.dtsi:2716 */
			spi1_sck_pa5: spi1_sck_pa5 {
				pinmux = < 0xa5 >;             /* in modules/hal/stm32/dts/st/l4/stm32l496z(e-g)tx-pinctrl.dtsi:2717 */
				bias-pull-down;                /* in modules/hal/stm32/dts/st/l4/stm32l496z(e-g)tx-pinctrl.dtsi:2718 */
				slew-rate = "very-high-speed"; /* in modules/hal/stm32/dts/st/l4/stm32l496z(e-g)tx-pinctrl.dtsi:2719 */
				phandle = < 0xf >;             /* in zephyr/boards/st/nucleo_l496zg/nucleo_l496zg.dts:172 */
			};

			/* node '/soc/pin-controller@48000000/tim1_ch1_pe9' defined in modules/hal/stm32/dts/st/l4/stm32l496z(e-g)tx-pinctrl.dtsi:2890 */
			tim1_ch1_pe9: tim1_ch1_pe9 {
				pinmux = < 0x921 >; /* in modules/hal/stm32/dts/st/l4/stm32l496z(e-g)tx-pinctrl.dtsi:2891 */
				phandle = < 0xc >;  /* in zephyr/boards/st/nucleo_l496zg/nucleo_l496zg.dts:133 */
			};

			/* node '/soc/pin-controller@48000000/tim1_ch2_pe11' defined in modules/hal/stm32/dts/st/l4/stm32l496z(e-g)tx-pinctrl.dtsi:2898 */
			tim1_ch2_pe11: tim1_ch2_pe11 {
				pinmux = < 0x961 >; /* in modules/hal/stm32/dts/st/l4/stm32l496z(e-g)tx-pinctrl.dtsi:2899 */
				phandle = < 0xd >;  /* in zephyr/boards/st/nucleo_l496zg/nucleo_l496zg.dts:133 */
			};

			/* node '/soc/pin-controller@48000000/tim1_ch3_pe13' defined in modules/hal/stm32/dts/st/l4/stm32l496z(e-g)tx-pinctrl.dtsi:2906 */
			tim1_ch3_pe13: tim1_ch3_pe13 {
				pinmux = < 0x9a1 >; /* in modules/hal/stm32/dts/st/l4/stm32l496z(e-g)tx-pinctrl.dtsi:2907 */
				phandle = < 0xe >;  /* in zephyr/boards/st/nucleo_l496zg/nucleo_l496zg.dts:133 */
			};

			/* node '/soc/pin-controller@48000000/tim2_ch1_pa0' defined in modules/hal/stm32/dts/st/l4/stm32l496z(e-g)tx-pinctrl.dtsi:2914 */
			tim2_ch1_pa0: tim2_ch1_pa0 {
				pinmux = < 0x1 >;  /* in modules/hal/stm32/dts/st/l4/stm32l496z(e-g)tx-pinctrl.dtsi:2915 */
				phandle = < 0x4 >; /* in zephyr/boards/st/nucleo_l496zg/nucleo_l496zg.dts:145 */
			};

			/* node '/soc/pin-controller@48000000/tim15_ch1_pb14' defined in modules/hal/stm32/dts/st/l4/stm32l496z(e-g)tx-pinctrl.dtsi:3070 */
			tim15_ch1_pb14: tim15_ch1_pb14 {
				pinmux = < 0x3ce >; /* in modules/hal/stm32/dts/st/l4/stm32l496z(e-g)tx-pinctrl.dtsi:3071 */
				phandle = < 0x13 >; /* in zephyr/boards/st/nucleo_l496zg/nucleo_l496zg.dts:156 */
			};

			/* node '/soc/pin-controller@48000000/lpuart1_rx_pg8' defined in modules/hal/stm32/dts/st/l4/stm32l496z(e-g)tx-pinctrl.dtsi:3562 */
			lpuart1_rx_pg8: lpuart1_rx_pg8 {
				pinmux = < 0xd08 >; /* in modules/hal/stm32/dts/st/l4/stm32l496z(e-g)tx-pinctrl.dtsi:3563 */
				phandle = < 0xb >;  /* in zephyr/boards/st/nucleo_l496zg/nucleo_l496zg.dts:116 */
			};

			/* node '/soc/pin-controller@48000000/usart2_rx_pd6' defined in modules/hal/stm32/dts/st/l4/stm32l496z(e-g)tx-pinctrl.dtsi:3578 */
			usart2_rx_pd6: usart2_rx_pd6 {
				pinmux = < 0x6c7 >; /* in modules/hal/stm32/dts/st/l4/stm32l496z(e-g)tx-pinctrl.dtsi:3579 */
				phandle = < 0x6 >;  /* in zephyr/boards/st/nucleo_l496zg/nucleo_l496zg.dts:102 */
			};

			/* node '/soc/pin-controller@48000000/usart3_rx_pd9' defined in modules/hal/stm32/dts/st/l4/stm32l496z(e-g)tx-pinctrl.dtsi:3594 */
			usart3_rx_pd9: usart3_rx_pd9 {
				pinmux = < 0x727 >; /* in modules/hal/stm32/dts/st/l4/stm32l496z(e-g)tx-pinctrl.dtsi:3595 */
				phandle = < 0x16 >; /* in zephyr/boards/st/nucleo_l496zg/nucleo_l496zg.dts:109 */
			};

			/* node '/soc/pin-controller@48000000/lpuart1_tx_pg7' defined in modules/hal/stm32/dts/st/l4/stm32l496z(e-g)tx-pinctrl.dtsi:3636 */
			lpuart1_tx_pg7: lpuart1_tx_pg7 {
				pinmux = < 0xce8 >; /* in modules/hal/stm32/dts/st/l4/stm32l496z(e-g)tx-pinctrl.dtsi:3637 */
				bias-pull-up;       /* in modules/hal/stm32/dts/st/l4/stm32l496z(e-g)tx-pinctrl.dtsi:3638 */
				phandle = < 0xa >;  /* in zephyr/boards/st/nucleo_l496zg/nucleo_l496zg.dts:116 */
			};

			/* node '/soc/pin-controller@48000000/usart2_tx_pd5' defined in modules/hal/stm32/dts/st/l4/stm32l496z(e-g)tx-pinctrl.dtsi:3651 */
			usart2_tx_pd5: usart2_tx_pd5 {
				pinmux = < 0x6a7 >; /* in modules/hal/stm32/dts/st/l4/stm32l496z(e-g)tx-pinctrl.dtsi:3652 */
				bias-pull-up;       /* in modules/hal/stm32/dts/st/l4/stm32l496z(e-g)tx-pinctrl.dtsi:3653 */
				phandle = < 0x5 >;  /* in zephyr/boards/st/nucleo_l496zg/nucleo_l496zg.dts:102 */
			};

			/* node '/soc/pin-controller@48000000/usart3_tx_pd8' defined in modules/hal/stm32/dts/st/l4/stm32l496z(e-g)tx-pinctrl.dtsi:3671 */
			usart3_tx_pd8: usart3_tx_pd8 {
				pinmux = < 0x707 >; /* in modules/hal/stm32/dts/st/l4/stm32l496z(e-g)tx-pinctrl.dtsi:3672 */
				bias-pull-up;       /* in modules/hal/stm32/dts/st/l4/stm32l496z(e-g)tx-pinctrl.dtsi:3673 */
				phandle = < 0x15 >; /* in zephyr/boards/st/nucleo_l496zg/nucleo_l496zg.dts:109 */
			};

			/* node '/soc/pin-controller@48000000/usb_otg_fs_dm_pa11' defined in modules/hal/stm32/dts/st/l4/stm32l496z(e-g)tx-pinctrl.dtsi:3704 */
			usb_otg_fs_dm_pa11: usb_otg_fs_dm_pa11 {
				pinmux = < 0x16a >; /* in modules/hal/stm32/dts/st/l4/stm32l496z(e-g)tx-pinctrl.dtsi:3705 */
				phandle = < 0x19 >; /* in zephyr/boards/st/nucleo_l496zg/nucleo_l496zg.dts:123 */
			};

			/* node '/soc/pin-controller@48000000/usb_otg_fs_dp_pa12' defined in modules/hal/stm32/dts/st/l4/stm32l496z(e-g)tx-pinctrl.dtsi:3708 */
			usb_otg_fs_dp_pa12: usb_otg_fs_dp_pa12 {
				pinmux = < 0x18a >; /* in modules/hal/stm32/dts/st/l4/stm32l496z(e-g)tx-pinctrl.dtsi:3709 */
				phandle = < 0x1a >; /* in zephyr/boards/st/nucleo_l496zg/nucleo_l496zg.dts:123 */
			};
		};

		/* node '/soc/adc@50040000' defined in zephyr/dts/arm/st/l4/stm32l4.dtsi:542 */
		adc123_common: adc@50040000 {
			compatible = "st,stm32-adc";                                /* in zephyr/dts/arm/st/l4/stm32l4.dtsi:543 */
			reg = < 0x50040000 0x400 >;                                 /* in zephyr/dts/arm/st/l4/stm32l4.dtsi:544 */
			ranges;                                                     /* in zephyr/dts/arm/st/l4/stm32l4.dtsi:545 */
			#address-cells = < 0x1 >;                                   /* in zephyr/dts/arm/st/l4/stm32l4.dtsi:546 */
			#size-cells = < 0x1 >;                                      /* in zephyr/dts/arm/st/l4/stm32l4.dtsi:547 */
			clocks = < &rcc 0x4c 0x2000 >;                              /* in zephyr/dts/arm/st/l4/stm32l4.dtsi:548 */
			clock-names = "adcx";                                       /* in zephyr/dts/arm/st/l4/stm32l4.dtsi:549 */
			sampling-times = < 0x3 0x7 0xd 0x19 0x30 0x5d 0xf8 0x281 >; /* in zephyr/dts/arm/st/l4/stm32l4.dtsi:550 */
			st,adc-resolutions = < 0xc 0xa 0x8 0x6 >;                   /* in zephyr/dts/arm/st/l4/stm32l4.dtsi:551 */
			st,adc-sequencer = "programmable";                          /* in zephyr/dts/arm/st/l4/stm32l4.dtsi:552 */
			st,adc-oversampler = "minimal";                             /* in zephyr/dts/arm/st/l4/stm32l4.dtsi:553 */
			st,adc-internal-regulator = "startup-sw-delay";             /* in zephyr/dts/arm/st/l4/stm32l4.dtsi:554 */
			st,adc-has-deep-powerdown;                                  /* in zephyr/dts/arm/st/l4/stm32l4.dtsi:555 */
			st,adc-has-differential-support;                            /* in zephyr/dts/arm/st/l4/stm32l4.dtsi:556 */
			st,adc-has-injected-support;                                /* in zephyr/dts/arm/st/l4/stm32l4.dtsi:557 */
			status = "disabled";                                        /* in zephyr/dts/arm/st/l4/stm32l4.dtsi:558 */

			/* node '/soc/adc@50040000/adc@50040000' defined in zephyr/dts/arm/st/l4/stm32l4.dtsi:560 */
			adc1: adc@50040000 {
				reg = < 0x50040000 0x100 >;  /* in zephyr/dts/arm/st/l4/stm32l4.dtsi:561 */
				interrupts = < 0x12 0x0 >;   /* in zephyr/dts/arm/st/l4/stm32l4.dtsi:562 */
				#io-channel-cells = < 0x1 >; /* in zephyr/dts/arm/st/l4/stm32l4.dtsi:563 */
				status = "disabled";         /* in zephyr/dts/arm/st/l4/stm32l4.dtsi:564 */
				phandle = < 0x21 >;          /* in zephyr/dts/arm/st/l4/stm32l4.dtsi:605 */
			};

			/* node '/soc/adc@50040000/adc@50040100' defined in zephyr/dts/arm/st/l4/stm32l4.dtsi:567 */
			adc2: adc@50040100 {
				reg = < 0x50040100 0x100 >;  /* in zephyr/dts/arm/st/l4/stm32l4.dtsi:568 */
				interrupts = < 0x12 0x0 >;   /* in zephyr/dts/arm/st/l4/stm32l4.dtsi:569 */
				#io-channel-cells = < 0x1 >; /* in zephyr/dts/arm/st/l4/stm32l4.dtsi:570 */
				status = "disabled";         /* in zephyr/dts/arm/st/l4/stm32l4.dtsi:571 */
			};

			/* node '/soc/adc@50040000/adc@50040200' defined in zephyr/dts/arm/st/l4/stm32l471.dtsi:416 */
			adc3: adc@50040200 {
				reg = < 0x50040200 0x100 >;  /* in zephyr/dts/arm/st/l4/stm32l471.dtsi:417 */
				interrupts = < 0x2f 0x0 >;   /* in zephyr/dts/arm/st/l4/stm32l471.dtsi:418 */
				#io-channel-cells = < 0x1 >; /* in zephyr/dts/arm/st/l4/stm32l471.dtsi:419 */
				status = "disabled";         /* in zephyr/dts/arm/st/l4/stm32l471.dtsi:420 */
			};
		};

		/* node '/soc/rng@50060800' defined in zephyr/dts/arm/st/l4/stm32l4.dtsi:575 */
		rng: rng@50060800 {
			compatible = "st,stm32-rng";    /* in zephyr/dts/arm/st/l4/stm32l4.dtsi:576 */
			reg = < 0x50060800 0x400 >;     /* in zephyr/dts/arm/st/l4/stm32l4.dtsi:577 */
			interrupts = < 0x50 0x0 >;      /* in zephyr/dts/arm/st/l4/stm32l4.dtsi:578 */
			status = "disabled";            /* in zephyr/dts/arm/st/l4/stm32l4.dtsi:584 */
			clocks = < &rcc 0x4c 0x40000 >,
			         < &rcc 0x6 0x3a0088 >; /* in zephyr/dts/arm/st/l4/stm32l496.dtsi:75 */
		};

		/* node '/soc/spi@a0001000' defined in zephyr/dts/arm/st/l4/stm32l4.dtsi:587 */
		quadspi: spi@a0001000 {
			compatible = "st,stm32-qspi";    /* in zephyr/dts/arm/st/l4/stm32l4.dtsi:588 */
			reg = < 0xa0001000 0x400 >,
			      < 0x90000000 0x10000000 >; /* in zephyr/dts/arm/st/l4/stm32l4.dtsi:589 */
			#address-cells = < 0x1 >;        /* in zephyr/dts/arm/st/l4/stm32l4.dtsi:590 */
			#size-cells = < 0x0 >;           /* in zephyr/dts/arm/st/l4/stm32l4.dtsi:591 */
			interrupts = < 0x47 0x0 >;       /* in zephyr/dts/arm/st/l4/stm32l4.dtsi:592 */
			clocks = < &rcc 0x50 0x100 >;    /* in zephyr/dts/arm/st/l4/stm32l4.dtsi:593 */
			status = "disabled";             /* in zephyr/dts/arm/st/l4/stm32l4.dtsi:594 */
		};

		/* node '/soc/timers@40000400' defined in zephyr/dts/arm/st/l4/stm32l471.dtsi:21 */
		timers3: timers@40000400 {
			compatible = "st,stm32-timers"; /* in zephyr/dts/arm/st/l4/stm32l471.dtsi:22 */
			reg = < 0x40000400 0x400 >;     /* in zephyr/dts/arm/st/l4/stm32l471.dtsi:23 */
			clocks = < &rcc 0x58 0x2 >,
			         < &rcc 0x9 0xff >;     /* in zephyr/dts/arm/st/l4/stm32l471.dtsi:24 */
			resets = < &rctl 0x701 >;       /* in zephyr/dts/arm/st/l4/stm32l471.dtsi:26 */
			interrupts = < 0x1d 0x0 >;      /* in zephyr/dts/arm/st/l4/stm32l471.dtsi:27 */
			interrupt-names = "global";     /* in zephyr/dts/arm/st/l4/stm32l471.dtsi:28 */
			st,prescaler = < 0x0 >;         /* in zephyr/dts/arm/st/l4/stm32l471.dtsi:29 */
			status = "disabled";            /* in zephyr/dts/arm/st/l4/stm32l471.dtsi:30 */

			/* node '/soc/timers@40000400/pwm' defined in zephyr/dts/arm/st/l4/stm32l471.dtsi:32 */
			pwm {
				compatible = "st,stm32-pwm"; /* in zephyr/dts/arm/st/l4/stm32l471.dtsi:33 */
				#pwm-cells = < 0x3 >;        /* in zephyr/dts/arm/st/l4/stm32l471.dtsi:34 */
				status = "disabled";         /* in zephyr/dts/arm/st/l4/stm32l471.dtsi:35 */
			};

			/* node '/soc/timers@40000400/counter' defined in zephyr/dts/arm/st/l4/stm32l471.dtsi:38 */
			counter {
				compatible = "st,stm32-counter"; /* in zephyr/dts/arm/st/l4/stm32l471.dtsi:39 */
				status = "disabled";             /* in zephyr/dts/arm/st/l4/stm32l471.dtsi:40 */
			};

			/* node '/soc/timers@40000400/qdec' defined in zephyr/dts/arm/st/l4/stm32l471.dtsi:43 */
			qdec {
				compatible = "st,stm32-qdec";    /* in zephyr/dts/arm/st/l4/stm32l471.dtsi:44 */
				st,input-filter-level = < 0x0 >; /* in zephyr/dts/arm/st/l4/stm32l471.dtsi:45 */
				status = "disabled";             /* in zephyr/dts/arm/st/l4/stm32l471.dtsi:46 */
			};
		};

		/* node '/soc/timers@40000800' defined in zephyr/dts/arm/st/l4/stm32l471.dtsi:50 */
		timers4: timers@40000800 {
			compatible = "st,stm32-timers"; /* in zephyr/dts/arm/st/l4/stm32l471.dtsi:51 */
			reg = < 0x40000800 0x400 >;     /* in zephyr/dts/arm/st/l4/stm32l471.dtsi:52 */
			clocks = < &rcc 0x58 0x4 >,
			         < &rcc 0x9 0xff >;     /* in zephyr/dts/arm/st/l4/stm32l471.dtsi:53 */
			resets = < &rctl 0x702 >;       /* in zephyr/dts/arm/st/l4/stm32l471.dtsi:55 */
			interrupts = < 0x1e 0x0 >;      /* in zephyr/dts/arm/st/l4/stm32l471.dtsi:56 */
			interrupt-names = "global";     /* in zephyr/dts/arm/st/l4/stm32l471.dtsi:57 */
			st,prescaler = < 0x0 >;         /* in zephyr/dts/arm/st/l4/stm32l471.dtsi:58 */
			status = "disabled";            /* in zephyr/dts/arm/st/l4/stm32l471.dtsi:59 */

			/* node '/soc/timers@40000800/pwm' defined in zephyr/dts/arm/st/l4/stm32l471.dtsi:61 */
			pwm {
				compatible = "st,stm32-pwm"; /* in zephyr/dts/arm/st/l4/stm32l471.dtsi:62 */
				#pwm-cells = < 0x3 >;        /* in zephyr/dts/arm/st/l4/stm32l471.dtsi:63 */
				status = "disabled";         /* in zephyr/dts/arm/st/l4/stm32l471.dtsi:64 */
			};

			/* node '/soc/timers@40000800/counter' defined in zephyr/dts/arm/st/l4/stm32l471.dtsi:67 */
			counter {
				compatible = "st,stm32-counter"; /* in zephyr/dts/arm/st/l4/stm32l471.dtsi:68 */
				status = "disabled";             /* in zephyr/dts/arm/st/l4/stm32l471.dtsi:69 */
			};

			/* node '/soc/timers@40000800/qdec' defined in zephyr/dts/arm/st/l4/stm32l471.dtsi:72 */
			qdec {
				compatible = "st,stm32-qdec";    /* in zephyr/dts/arm/st/l4/stm32l471.dtsi:73 */
				st,input-filter-level = < 0x0 >; /* in zephyr/dts/arm/st/l4/stm32l471.dtsi:74 */
				status = "disabled";             /* in zephyr/dts/arm/st/l4/stm32l471.dtsi:75 */
			};
		};

		/* node '/soc/timers@40000c00' defined in zephyr/dts/arm/st/l4/stm32l471.dtsi:79 */
		timers5: timers@40000c00 {
			compatible = "st,stm32-timers"; /* in zephyr/dts/arm/st/l4/stm32l471.dtsi:80 */
			reg = < 0x40000c00 0x400 >;     /* in zephyr/dts/arm/st/l4/stm32l471.dtsi:81 */
			clocks = < &rcc 0x58 0x8 >,
			         < &rcc 0x9 0xff >;     /* in zephyr/dts/arm/st/l4/stm32l471.dtsi:82 */
			resets = < &rctl 0x703 >;       /* in zephyr/dts/arm/st/l4/stm32l471.dtsi:84 */
			interrupts = < 0x32 0x0 >;      /* in zephyr/dts/arm/st/l4/stm32l471.dtsi:85 */
			interrupt-names = "global";     /* in zephyr/dts/arm/st/l4/stm32l471.dtsi:86 */
			st,prescaler = < 0x0 >;         /* in zephyr/dts/arm/st/l4/stm32l471.dtsi:87 */
			status = "disabled";            /* in zephyr/dts/arm/st/l4/stm32l471.dtsi:88 */

			/* node '/soc/timers@40000c00/pwm' defined in zephyr/dts/arm/st/l4/stm32l471.dtsi:90 */
			pwm {
				compatible = "st,stm32-pwm"; /* in zephyr/dts/arm/st/l4/stm32l471.dtsi:91 */
				#pwm-cells = < 0x3 >;        /* in zephyr/dts/arm/st/l4/stm32l471.dtsi:92 */
				status = "disabled";         /* in zephyr/dts/arm/st/l4/stm32l471.dtsi:93 */
			};

			/* node '/soc/timers@40000c00/counter' defined in zephyr/dts/arm/st/l4/stm32l471.dtsi:96 */
			counter {
				compatible = "st,stm32-counter"; /* in zephyr/dts/arm/st/l4/stm32l471.dtsi:97 */
				status = "disabled";             /* in zephyr/dts/arm/st/l4/stm32l471.dtsi:98 */
			};

			/* node '/soc/timers@40000c00/qdec' defined in zephyr/dts/arm/st/l4/stm32l471.dtsi:101 */
			qdec {
				compatible = "st,stm32-qdec";    /* in zephyr/dts/arm/st/l4/stm32l471.dtsi:102 */
				st,input-filter-level = < 0x0 >; /* in zephyr/dts/arm/st/l4/stm32l471.dtsi:103 */
				status = "disabled";             /* in zephyr/dts/arm/st/l4/stm32l471.dtsi:104 */
			};
		};

		/* node '/soc/timers@40001400' defined in zephyr/dts/arm/st/l4/stm32l471.dtsi:108 */
		timers7: timers@40001400 {
			compatible = "st,stm32-timers"; /* in zephyr/dts/arm/st/l4/stm32l471.dtsi:109 */
			reg = < 0x40001400 0x400 >;     /* in zephyr/dts/arm/st/l4/stm32l471.dtsi:110 */
			clocks = < &rcc 0x58 0x20 >,
			         < &rcc 0x9 0xff >;     /* in zephyr/dts/arm/st/l4/stm32l471.dtsi:111 */
			resets = < &rctl 0x705 >;       /* in zephyr/dts/arm/st/l4/stm32l471.dtsi:113 */
			interrupts = < 0x37 0x0 >;      /* in zephyr/dts/arm/st/l4/stm32l471.dtsi:114 */
			interrupt-names = "global";     /* in zephyr/dts/arm/st/l4/stm32l471.dtsi:115 */
			st,prescaler = < 0x0 >;         /* in zephyr/dts/arm/st/l4/stm32l471.dtsi:116 */
			status = "disabled";            /* in zephyr/dts/arm/st/l4/stm32l471.dtsi:117 */

			/* node '/soc/timers@40001400/counter' defined in zephyr/dts/arm/st/l4/stm32l471.dtsi:119 */
			counter {
				compatible = "st,stm32-counter"; /* in zephyr/dts/arm/st/l4/stm32l471.dtsi:120 */
				status = "disabled";             /* in zephyr/dts/arm/st/l4/stm32l471.dtsi:121 */
			};
		};

		/* node '/soc/spi@40003800' defined in zephyr/dts/arm/st/l4/stm32l471.dtsi:133 */
		spi2: spi@40003800 {
			compatible = "st,stm32-spi-fifo",
			             "st,stm32-spi";            /* in zephyr/dts/arm/st/l4/stm32l471.dtsi:134 */
			reg = < 0x40003800 0x400 >;             /* in zephyr/dts/arm/st/l4/stm32l471.dtsi:135 */
			#address-cells = < 0x1 >;               /* in zephyr/dts/arm/st/l4/stm32l471.dtsi:136 */
			#size-cells = < 0x0 >;                  /* in zephyr/dts/arm/st/l4/stm32l471.dtsi:137 */
			clocks = < &rcc 0x58 0x4000 >;          /* in zephyr/dts/arm/st/l4/stm32l471.dtsi:138 */
			interrupts = < 0x24 0x0 >;              /* in zephyr/dts/arm/st/l4/stm32l471.dtsi:139 */
			st,spi-data-width = "full-4-to-16-bit"; /* in zephyr/dts/arm/st/l4/stm32l471.dtsi:140 */
			status = "disabled";                    /* in zephyr/dts/arm/st/l4/stm32l471.dtsi:141 */
		};

		/* node '/soc/spi@40003c00' defined in zephyr/dts/arm/st/l4/stm32l471.dtsi:144 */
		spi3: spi@40003c00 {
			compatible = "st,stm32-spi-fifo",
			             "st,stm32-spi";            /* in zephyr/dts/arm/st/l4/stm32l471.dtsi:145 */
			reg = < 0x40003c00 0x400 >;             /* in zephyr/dts/arm/st/l4/stm32l471.dtsi:146 */
			#address-cells = < 0x1 >;               /* in zephyr/dts/arm/st/l4/stm32l471.dtsi:147 */
			#size-cells = < 0x0 >;                  /* in zephyr/dts/arm/st/l4/stm32l471.dtsi:148 */
			clocks = < &rcc 0x58 0x8000 >;          /* in zephyr/dts/arm/st/l4/stm32l471.dtsi:149 */
			interrupts = < 0x33 0x0 >;              /* in zephyr/dts/arm/st/l4/stm32l471.dtsi:150 */
			st,spi-data-width = "full-4-to-16-bit"; /* in zephyr/dts/arm/st/l4/stm32l471.dtsi:151 */
			status = "disabled";                    /* in zephyr/dts/arm/st/l4/stm32l471.dtsi:152 */
		};

		/* node '/soc/serial@40004800' defined in zephyr/dts/arm/st/l4/stm32l471.dtsi:155 */
		usart3: serial@40004800 {
			compatible = "st,stm32-usart",
			             "st,stm32-uart";                  /* in zephyr/dts/arm/st/l4/stm32l471.dtsi:156 */
			reg = < 0x40004800 0x400 >;                    /* in zephyr/dts/arm/st/l4/stm32l471.dtsi:157 */
			clocks = < &rcc 0x58 0x40000 >;                /* in zephyr/dts/arm/st/l4/stm32l471.dtsi:158 */
			resets = < &rctl 0x712 >;                      /* in zephyr/dts/arm/st/l4/stm32l471.dtsi:159 */
			interrupts = < 0x27 0x0 >;                     /* in zephyr/dts/arm/st/l4/stm32l471.dtsi:160 */
			pinctrl-0 = < &usart3_tx_pd8 &usart3_rx_pd9 >; /* in zephyr/boards/st/nucleo_l496zg/nucleo_l496zg.dts:109 */
			pinctrl-names = "default";                     /* in zephyr/boards/st/nucleo_l496zg/nucleo_l496zg.dts:110 */
			current-speed = < 0x1c200 >;                   /* in zephyr/boards/st/nucleo_l496zg/nucleo_l496zg.dts:111 */
			status = "disabled";                           /* in ../projects/grp/daq-module/firmware/app.overlay:25 */
		};

		/* node '/soc/serial@40004c00' defined in zephyr/dts/arm/st/l4/stm32l471.dtsi:164 */
		uart4: serial@40004c00 {
			compatible = "st,stm32-uart";   /* in zephyr/dts/arm/st/l4/stm32l471.dtsi:165 */
			reg = < 0x40004c00 0x400 >;     /* in zephyr/dts/arm/st/l4/stm32l471.dtsi:166 */
			clocks = < &rcc 0x58 0x80000 >; /* in zephyr/dts/arm/st/l4/stm32l471.dtsi:167 */
			resets = < &rctl 0x713 >;       /* in zephyr/dts/arm/st/l4/stm32l471.dtsi:168 */
			interrupts = < 0x34 0x0 >;      /* in zephyr/dts/arm/st/l4/stm32l471.dtsi:169 */
			status = "disabled";            /* in zephyr/dts/arm/st/l4/stm32l471.dtsi:170 */
		};

		/* node '/soc/serial@40005000' defined in zephyr/dts/arm/st/l4/stm32l471.dtsi:173 */
		uart5: serial@40005000 {
			compatible = "st,stm32-uart";    /* in zephyr/dts/arm/st/l4/stm32l471.dtsi:174 */
			reg = < 0x40005000 0x400 >;      /* in zephyr/dts/arm/st/l4/stm32l471.dtsi:175 */
			clocks = < &rcc 0x58 0x100000 >; /* in zephyr/dts/arm/st/l4/stm32l471.dtsi:176 */
			resets = < &rctl 0x714 >;        /* in zephyr/dts/arm/st/l4/stm32l471.dtsi:177 */
			interrupts = < 0x35 0x0 >;       /* in zephyr/dts/arm/st/l4/stm32l471.dtsi:178 */
			status = "disabled";             /* in zephyr/dts/arm/st/l4/stm32l471.dtsi:179 */
		};

		/* node '/soc/i2c@40005800' defined in zephyr/dts/arm/st/l4/stm32l471.dtsi:182 */
		i2c2: i2c@40005800 {
			compatible = "st,stm32-i2c-v2";  /* in zephyr/dts/arm/st/l4/stm32l471.dtsi:183 */
			reg = < 0x40005800 0x400 >;      /* in zephyr/dts/arm/st/l4/stm32l471.dtsi:184 */
			clock-frequency = < 0x186a0 >;   /* in zephyr/dts/arm/st/l4/stm32l471.dtsi:185 */
			#address-cells = < 0x1 >;        /* in zephyr/dts/arm/st/l4/stm32l471.dtsi:186 */
			#size-cells = < 0x0 >;           /* in zephyr/dts/arm/st/l4/stm32l471.dtsi:187 */
			clocks = < &rcc 0x58 0x400000 >; /* in zephyr/dts/arm/st/l4/stm32l471.dtsi:188 */
			interrupts = < 0x21 0x0 >,
			             < 0x22 0x0 >;       /* in zephyr/dts/arm/st/l4/stm32l471.dtsi:189 */
			interrupt-names = "event",
			                  "error";       /* in zephyr/dts/arm/st/l4/stm32l471.dtsi:190 */
			status = "disabled";             /* in zephyr/dts/arm/st/l4/stm32l471.dtsi:191 */
			phandle = < 0x25 >;              /* in zephyr/dts/arm/st/l4/stm32l471.dtsi:433 */
		};

		/* node '/soc/can@40006400' defined in zephyr/dts/arm/st/l4/stm32l471.dtsi:194 */
		can1: can@40006400 {
			compatible = "st,stm32-bxcan";    /* in zephyr/dts/arm/st/l4/stm32l471.dtsi:195 */
			reg = < 0x40006400 0x400 >;       /* in zephyr/dts/arm/st/l4/stm32l471.dtsi:196 */
			interrupts = < 0x13 0x0 >,
			             < 0x14 0x0 >,
			             < 0x15 0x0 >,
			             < 0x16 0x0 >;        /* in zephyr/dts/arm/st/l4/stm32l471.dtsi:197 */
			interrupt-names = "TX",
			                  "RX0",
			                  "RX1",
			                  "SCE";          /* in zephyr/dts/arm/st/l4/stm32l471.dtsi:198 */
			clocks = < &rcc 0x58 0x2000000 >; /* in zephyr/dts/arm/st/l4/stm32l471.dtsi:199 */
			status = "disabled";              /* in zephyr/dts/arm/st/l4/stm32l471.dtsi:200 */
		};

		/* node '/soc/dac@40007400' defined in zephyr/dts/arm/st/l4/stm32l471.dtsi:203 */
		dac1: dac@40007400 {
			compatible = "st,stm32-dac";       /* in zephyr/dts/arm/st/l4/stm32l471.dtsi:204 */
			reg = < 0x40007400 0x400 >;        /* in zephyr/dts/arm/st/l4/stm32l471.dtsi:205 */
			clocks = < &rcc 0x58 0x20000000 >; /* in zephyr/dts/arm/st/l4/stm32l471.dtsi:206 */
			#io-channel-cells = < 0x1 >;       /* in zephyr/dts/arm/st/l4/stm32l471.dtsi:207 */
			status = "disabled";               /* in zephyr/dts/arm/st/l4/stm32l471.dtsi:208 */
		};

		/* node '/soc/sdmmc@40012800' defined in zephyr/dts/arm/st/l4/stm32l471.dtsi:211 */
		sdmmc1: sdmmc@40012800 {
			compatible = "st,stm32-sdmmc";  /* in zephyr/dts/arm/st/l4/stm32l471.dtsi:212 */
			reg = < 0x40012800 0x400 >;     /* in zephyr/dts/arm/st/l4/stm32l471.dtsi:213 */
			resets = < &rctl 0x80a >;       /* in zephyr/dts/arm/st/l4/stm32l471.dtsi:216 */
			interrupts = < 0x31 0x0 >;      /* in zephyr/dts/arm/st/l4/stm32l471.dtsi:217 */
			status = "disabled";            /* in zephyr/dts/arm/st/l4/stm32l471.dtsi:218 */
			clocks = < &rcc 0x60 0x400 >,
			         < &rcc 0x6 0x3a0088 >; /* in zephyr/dts/arm/st/l4/stm32l496.dtsi:45 */
		};

		/* node '/soc/timers@40013400' defined in zephyr/dts/arm/st/l4/stm32l471.dtsi:221 */
		timers8: timers@40013400 {
			compatible = "st,stm32-timers"; /* in zephyr/dts/arm/st/l4/stm32l471.dtsi:222 */
			reg = < 0x40013400 0x400 >;     /* in zephyr/dts/arm/st/l4/stm32l471.dtsi:223 */
			clocks = < &rcc 0x60 0x2000 >,
			         < &rcc 0xa 0xff >;     /* in zephyr/dts/arm/st/l4/stm32l471.dtsi:224 */
			resets = < &rctl 0x80d >;       /* in zephyr/dts/arm/st/l4/stm32l471.dtsi:226 */
			interrupts = < 0x2b 0x0 >,
			             < 0x2c 0x0 >,
			             < 0x2d 0x0 >,
			             < 0x2e 0x0 >;      /* in zephyr/dts/arm/st/l4/stm32l471.dtsi:227 */
			interrupt-names = "brk",
			                  "up",
			                  "trgcom",
			                  "cc";         /* in zephyr/dts/arm/st/l4/stm32l471.dtsi:228 */
			st,prescaler = < 0x0 >;         /* in zephyr/dts/arm/st/l4/stm32l471.dtsi:229 */
			status = "disabled";            /* in zephyr/dts/arm/st/l4/stm32l471.dtsi:230 */

			/* node '/soc/timers@40013400/pwm' defined in zephyr/dts/arm/st/l4/stm32l471.dtsi:232 */
			pwm {
				compatible = "st,stm32-pwm"; /* in zephyr/dts/arm/st/l4/stm32l471.dtsi:233 */
				#pwm-cells = < 0x3 >;        /* in zephyr/dts/arm/st/l4/stm32l471.dtsi:234 */
				status = "disabled";         /* in zephyr/dts/arm/st/l4/stm32l471.dtsi:235 */
			};

			/* node '/soc/timers@40013400/counter' defined in zephyr/dts/arm/st/l4/stm32l471.dtsi:238 */
			counter {
				compatible = "st,stm32-counter"; /* in zephyr/dts/arm/st/l4/stm32l471.dtsi:239 */
				status = "disabled";             /* in zephyr/dts/arm/st/l4/stm32l471.dtsi:240 */
			};

			/* node '/soc/timers@40013400/qdec' defined in zephyr/dts/arm/st/l4/stm32l471.dtsi:243 */
			qdec {
				compatible = "st,stm32-qdec";    /* in zephyr/dts/arm/st/l4/stm32l471.dtsi:244 */
				st,input-filter-level = < 0x0 >; /* in zephyr/dts/arm/st/l4/stm32l471.dtsi:245 */
				status = "disabled";             /* in zephyr/dts/arm/st/l4/stm32l471.dtsi:246 */
			};
		};

		/* node '/soc/timers@40014800' defined in zephyr/dts/arm/st/l4/stm32l471.dtsi:250 */
		timers17: timers@40014800 {
			compatible = "st,stm32-timers"; /* in zephyr/dts/arm/st/l4/stm32l471.dtsi:251 */
			reg = < 0x40014800 0x400 >;     /* in zephyr/dts/arm/st/l4/stm32l471.dtsi:252 */
			clocks = < &rcc 0x60 0x40000 >,
			         < &rcc 0xa 0xff >;     /* in zephyr/dts/arm/st/l4/stm32l471.dtsi:253 */
			resets = < &rctl 0x812 >;       /* in zephyr/dts/arm/st/l4/stm32l471.dtsi:255 */
			interrupts = < 0x1a 0x0 >;      /* in zephyr/dts/arm/st/l4/stm32l471.dtsi:256 */
			interrupt-names = "global";     /* in zephyr/dts/arm/st/l4/stm32l471.dtsi:257 */
			st,prescaler = < 0x0 >;         /* in zephyr/dts/arm/st/l4/stm32l471.dtsi:258 */
			status = "disabled";            /* in zephyr/dts/arm/st/l4/stm32l471.dtsi:259 */

			/* node '/soc/timers@40014800/pwm' defined in zephyr/dts/arm/st/l4/stm32l471.dtsi:261 */
			pwm {
				compatible = "st,stm32-pwm"; /* in zephyr/dts/arm/st/l4/stm32l471.dtsi:262 */
				#pwm-cells = < 0x3 >;        /* in zephyr/dts/arm/st/l4/stm32l471.dtsi:263 */
				status = "disabled";         /* in zephyr/dts/arm/st/l4/stm32l471.dtsi:264 */
			};

			/* node '/soc/timers@40014800/counter' defined in zephyr/dts/arm/st/l4/stm32l471.dtsi:267 */
			counter {
				compatible = "st,stm32-counter"; /* in zephyr/dts/arm/st/l4/stm32l471.dtsi:268 */
				status = "disabled";             /* in zephyr/dts/arm/st/l4/stm32l471.dtsi:269 */
			};
		};

		/* node '/soc/sai1@40015400' defined in zephyr/dts/arm/st/l4/stm32l471.dtsi:273 */
		sai1: sai1@40015400 {
			compatible = "st,stm32-sai";     /* in zephyr/dts/arm/st/l4/stm32l471.dtsi:274 */
			reg = < 0x40015400 0x400 >;      /* in zephyr/dts/arm/st/l4/stm32l471.dtsi:275 */
			ranges;                          /* in zephyr/dts/arm/st/l4/stm32l471.dtsi:276 */
			#address-cells = < 0x1 >;        /* in zephyr/dts/arm/st/l4/stm32l471.dtsi:277 */
			#size-cells = < 0x1 >;           /* in zephyr/dts/arm/st/l4/stm32l471.dtsi:278 */
			clocks = < &rcc 0x60 0x200000 >,
			         < &rcc 0xe 0x360088 >;  /* in zephyr/dts/arm/st/l4/stm32l471.dtsi:279 */
			clock-names = "sai_ck",
			              "sai_ker_ck";      /* in zephyr/dts/arm/st/l4/stm32l471.dtsi:281 */
			status = "disabled";             /* in zephyr/dts/arm/st/l4/stm32l471.dtsi:282 */

			/* node '/soc/sai1@40015400/sai1a@40015404' defined in zephyr/dts/arm/st/l4/stm32l471.dtsi:284 */
			sai1_a: sai1a@40015404 {
				reg = < 0x40015404 0x20 >;        /* in zephyr/dts/arm/st/l4/stm32l471.dtsi:285 */
				dmas = < &dma2 0x1 0x1 0x22800 >; /* in zephyr/dts/arm/st/l4/stm32l471.dtsi:286 */
				#address-cells = < 0x1 >;         /* in zephyr/dts/arm/st/l4/stm32l471.dtsi:287 */
				#size-cells = < 0x0 >;            /* in zephyr/dts/arm/st/l4/stm32l471.dtsi:288 */
				status = "disabled";              /* in zephyr/dts/arm/st/l4/stm32l471.dtsi:289 */
			};

			/* node '/soc/sai1@40015400/sai1b@40015424' defined in zephyr/dts/arm/st/l4/stm32l471.dtsi:292 */
			sai1_b: sai1b@40015424 {
				reg = < 0x40015424 0x20 >;        /* in zephyr/dts/arm/st/l4/stm32l471.dtsi:293 */
				dmas = < &dma2 0x2 0x1 0x22800 >; /* in zephyr/dts/arm/st/l4/stm32l471.dtsi:294 */
				#address-cells = < 0x1 >;         /* in zephyr/dts/arm/st/l4/stm32l471.dtsi:295 */
				#size-cells = < 0x0 >;            /* in zephyr/dts/arm/st/l4/stm32l471.dtsi:296 */
				status = "disabled";              /* in zephyr/dts/arm/st/l4/stm32l471.dtsi:297 */
			};
		};

		/* node '/soc/sai2@40015800' defined in zephyr/dts/arm/st/l4/stm32l471.dtsi:301 */
		sai2: sai2@40015800 {
			compatible = "st,stm32-sai";     /* in zephyr/dts/arm/st/l4/stm32l471.dtsi:302 */
			reg = < 0x40015800 0x400 >;      /* in zephyr/dts/arm/st/l4/stm32l471.dtsi:303 */
			ranges;                          /* in zephyr/dts/arm/st/l4/stm32l471.dtsi:304 */
			#address-cells = < 0x1 >;        /* in zephyr/dts/arm/st/l4/stm32l471.dtsi:305 */
			#size-cells = < 0x1 >;           /* in zephyr/dts/arm/st/l4/stm32l471.dtsi:306 */
			clocks = < &rcc 0x60 0x400000 >,
			         < &rcc 0xe 0x380088 >;  /* in zephyr/dts/arm/st/l4/stm32l471.dtsi:307 */
			clock-names = "sai_ck",
			              "sai_ker_ck";      /* in zephyr/dts/arm/st/l4/stm32l471.dtsi:309 */
			status = "disabled";             /* in zephyr/dts/arm/st/l4/stm32l471.dtsi:310 */

			/* node '/soc/sai2@40015800/sai2a@40015804' defined in zephyr/dts/arm/st/l4/stm32l471.dtsi:312 */
			sai2_a: sai2a@40015804 {
				reg = < 0x40015804 0x20 >;        /* in zephyr/dts/arm/st/l4/stm32l471.dtsi:313 */
				dmas = < &dma2 0x3 0x1 0x22800 >; /* in zephyr/dts/arm/st/l4/stm32l471.dtsi:314 */
				#address-cells = < 0x1 >;         /* in zephyr/dts/arm/st/l4/stm32l471.dtsi:315 */
				#size-cells = < 0x0 >;            /* in zephyr/dts/arm/st/l4/stm32l471.dtsi:316 */
				status = "disabled";              /* in zephyr/dts/arm/st/l4/stm32l471.dtsi:317 */
			};

			/* node '/soc/sai2@40015800/sai2b@40015824' defined in zephyr/dts/arm/st/l4/stm32l471.dtsi:320 */
			sai2_b: sai2b@40015824 {
				reg = < 0x40015824 0x20 >;        /* in zephyr/dts/arm/st/l4/stm32l471.dtsi:321 */
				dmas = < &dma2 0x4 0x1 0x22800 >; /* in zephyr/dts/arm/st/l4/stm32l471.dtsi:322 */
				#address-cells = < 0x1 >;         /* in zephyr/dts/arm/st/l4/stm32l471.dtsi:323 */
				#size-cells = < 0x0 >;            /* in zephyr/dts/arm/st/l4/stm32l471.dtsi:324 */
				status = "disabled";              /* in zephyr/dts/arm/st/l4/stm32l471.dtsi:325 */
			};
		};

		/* node '/soc/dfsdm@40016000' defined in zephyr/dts/arm/st/l4/stm32l471.dtsi:329 */
		dfsdm: dfsdm@40016000 {
			compatible = "st,stm32-dfsdm";    /* in zephyr/dts/arm/st/l4/stm32l471.dtsi:330 */
			reg = < 0x40016000 0x400 >;       /* in zephyr/dts/arm/st/l4/stm32l471.dtsi:331 */
			clocks = < &rcc 0x60 0x1000000 >,
			         < &rcc 0xe 0xff >;       /* in zephyr/dts/arm/st/l4/stm32l471.dtsi:332 */
			clock-names = "pclk",
			              "aclk";             /* in zephyr/dts/arm/st/l4/stm32l471.dtsi:334 */
			resets = < &rctl 0x818 >;         /* in zephyr/dts/arm/st/l4/stm32l471.dtsi:335 */
			#address-cells = < 0x1 >;         /* in zephyr/dts/arm/st/l4/stm32l471.dtsi:336 */
			#size-cells = < 0x0 >;            /* in zephyr/dts/arm/st/l4/stm32l471.dtsi:337 */
			status = "disabled";              /* in zephyr/dts/arm/st/l4/stm32l471.dtsi:338 */

			/* node '/soc/dfsdm@40016000/filter@0' defined in zephyr/dts/arm/st/l4/stm32l471.dtsi:340 */
			pdm0: filter@0 {
				compatible = "st,stm32-dfsdm-dmic"; /* in zephyr/dts/arm/st/l4/stm32l471.dtsi:341 */
				reg = < 0x0 >;                      /* in zephyr/dts/arm/st/l4/stm32l471.dtsi:342 */
				interrupts = < 0x3d 0x0 >;          /* in zephyr/dts/arm/st/l4/stm32l471.dtsi:343 */
				filter-order = < 0x5 >;             /* in zephyr/dts/arm/st/l4/stm32l471.dtsi:344 */
				#address-cells = < 0x1 >;           /* in zephyr/dts/arm/st/l4/stm32l471.dtsi:345 */
				#size-cells = < 0x0 >;              /* in zephyr/dts/arm/st/l4/stm32l471.dtsi:346 */
				status = "disabled";                /* in zephyr/dts/arm/st/l4/stm32l471.dtsi:347 */
			};

			/* node '/soc/dfsdm@40016000/filter@1' defined in zephyr/dts/arm/st/l4/stm32l471.dtsi:350 */
			pdm1: filter@1 {
				compatible = "st,stm32-dfsdm-dmic"; /* in zephyr/dts/arm/st/l4/stm32l471.dtsi:351 */
				reg = < 0x1 >;                      /* in zephyr/dts/arm/st/l4/stm32l471.dtsi:352 */
				interrupts = < 0x3e 0x0 >;          /* in zephyr/dts/arm/st/l4/stm32l471.dtsi:353 */
				filter-order = < 0x5 >;             /* in zephyr/dts/arm/st/l4/stm32l471.dtsi:354 */
				#address-cells = < 0x1 >;           /* in zephyr/dts/arm/st/l4/stm32l471.dtsi:355 */
				#size-cells = < 0x0 >;              /* in zephyr/dts/arm/st/l4/stm32l471.dtsi:356 */
				status = "disabled";                /* in zephyr/dts/arm/st/l4/stm32l471.dtsi:357 */
			};

			/* node '/soc/dfsdm@40016000/filter@2' defined in zephyr/dts/arm/st/l4/stm32l471.dtsi:360 */
			pdm2: filter@2 {
				compatible = "st,stm32-dfsdm-dmic"; /* in zephyr/dts/arm/st/l4/stm32l471.dtsi:361 */
				reg = < 0x2 >;                      /* in zephyr/dts/arm/st/l4/stm32l471.dtsi:362 */
				interrupts = < 0x3f 0x0 >;          /* in zephyr/dts/arm/st/l4/stm32l471.dtsi:363 */
				filter-order = < 0x5 >;             /* in zephyr/dts/arm/st/l4/stm32l471.dtsi:364 */
				#address-cells = < 0x1 >;           /* in zephyr/dts/arm/st/l4/stm32l471.dtsi:365 */
				#size-cells = < 0x0 >;              /* in zephyr/dts/arm/st/l4/stm32l471.dtsi:366 */
				status = "disabled";                /* in zephyr/dts/arm/st/l4/stm32l471.dtsi:367 */
			};

			/* node '/soc/dfsdm@40016000/filter@3' defined in zephyr/dts/arm/st/l4/stm32l471.dtsi:370 */
			pdm3: filter@3 {
				compatible = "st,stm32-dfsdm-dmic"; /* in zephyr/dts/arm/st/l4/stm32l471.dtsi:371 */
				reg = < 0x3 >;                      /* in zephyr/dts/arm/st/l4/stm32l471.dtsi:372 */
				interrupts = < 0x2a 0x0 >;          /* in zephyr/dts/arm/st/l4/stm32l471.dtsi:373 */
				filter-order = < 0x5 >;             /* in zephyr/dts/arm/st/l4/stm32l471.dtsi:374 */
				#address-cells = < 0x1 >;           /* in zephyr/dts/arm/st/l4/stm32l471.dtsi:375 */
				#size-cells = < 0x0 >;              /* in zephyr/dts/arm/st/l4/stm32l471.dtsi:376 */
				status = "disabled";                /* in zephyr/dts/arm/st/l4/stm32l471.dtsi:377 */
			};
		};

		/* node '/soc/otgfs@50000000' defined in zephyr/dts/arm/st/l4/stm32l475.dtsi:13 */
		usbotg_fs: zephyr_udc0: otgfs@50000000 {
			compatible = "st,stm32-otgfs";                           /* in zephyr/dts/arm/st/l4/stm32l475.dtsi:14 */
			reg = < 0x50000000 0x40000 >;                            /* in zephyr/dts/arm/st/l4/stm32l475.dtsi:15 */
			interrupts = < 0x43 0x0 >;                               /* in zephyr/dts/arm/st/l4/stm32l475.dtsi:16 */
			interrupt-names = "otgfs";                               /* in zephyr/dts/arm/st/l4/stm32l475.dtsi:17 */
			num-bidir-endpoints = < 0x6 >;                           /* in zephyr/dts/arm/st/l4/stm32l475.dtsi:18 */
			ram-size = < 0x500 >;                                    /* in zephyr/dts/arm/st/l4/stm32l475.dtsi:19 */
			maximum-speed = "full-speed";                            /* in zephyr/dts/arm/st/l4/stm32l475.dtsi:20 */
			phys = < &otgfs_phy >;                                   /* in zephyr/dts/arm/st/l4/stm32l475.dtsi:21 */
			clocks = < &rcc 0x4c 0x1000 >,
			         < &rcc 0x6 0x3a0088 >;                          /* in zephyr/dts/arm/st/l4/stm32l496.dtsi:70 */
			pinctrl-0 = < &usb_otg_fs_dm_pa11 &usb_otg_fs_dp_pa12 >; /* in zephyr/boards/st/nucleo_l496zg/nucleo_l496zg.dts:123 */
			pinctrl-names = "default";                               /* in zephyr/boards/st/nucleo_l496zg/nucleo_l496zg.dts:124 */
			status = "disabled";                                     /* in ../projects/grp/daq-module/firmware/app.overlay:32 */
		};

		/* node '/soc/can@40006800' defined in zephyr/dts/arm/st/l4/stm32l496.dtsi:22 */
		can2: can@40006800 {
			compatible = "st,stm32-bxcan";    /* in zephyr/dts/arm/st/l4/stm32l496.dtsi:23 */
			reg = < 0x40006800 0x400 >;       /* in zephyr/dts/arm/st/l4/stm32l496.dtsi:24 */
			interrupts = < 0x56 0x0 >,
			             < 0x57 0x0 >,
			             < 0x58 0x0 >,
			             < 0x59 0x0 >;        /* in zephyr/dts/arm/st/l4/stm32l496.dtsi:25 */
			interrupt-names = "TX",
			                  "RX0",
			                  "RX1",
			                  "SCE";          /* in zephyr/dts/arm/st/l4/stm32l496.dtsi:26 */
			clocks = < &rcc 0x58 0x4000000 >; /* in zephyr/dts/arm/st/l4/stm32l496.dtsi:27 */
			master-can-reg = < 0x40006400 >;  /* in zephyr/dts/arm/st/l4/stm32l496.dtsi:28 */
			status = "disabled";              /* in zephyr/dts/arm/st/l4/stm32l496.dtsi:29 */
		};

		/* node '/soc/i2c@40008400' defined in zephyr/dts/arm/st/l4/stm32l496.dtsi:32 */
		i2c4: i2c@40008400 {
			compatible = "st,stm32-i2c-v2"; /* in zephyr/dts/arm/st/l4/stm32l496.dtsi:33 */
			reg = < 0x40008400 0x400 >;     /* in zephyr/dts/arm/st/l4/stm32l496.dtsi:34 */
			clock-frequency = < 0x186a0 >;  /* in zephyr/dts/arm/st/l4/stm32l496.dtsi:35 */
			#address-cells = < 0x1 >;       /* in zephyr/dts/arm/st/l4/stm32l496.dtsi:36 */
			#size-cells = < 0x0 >;          /* in zephyr/dts/arm/st/l4/stm32l496.dtsi:37 */
			clocks = < &rcc 0x5c 0x2 >;     /* in zephyr/dts/arm/st/l4/stm32l496.dtsi:38 */
			interrupts = < 0x53 0x0 >,
			             < 0x54 0x0 >;      /* in zephyr/dts/arm/st/l4/stm32l496.dtsi:39 */
			interrupt-names = "event",
			                  "error";      /* in zephyr/dts/arm/st/l4/stm32l496.dtsi:40 */
			status = "disabled";            /* in zephyr/dts/arm/st/l4/stm32l496.dtsi:41 */
			phandle = < 0x26 >;             /* in zephyr/dts/arm/st/l4/stm32l496.dtsi:88 */
		};

		/* node '/soc/dma@4002b000' defined in zephyr/dts/arm/st/l4/stm32l496.dtsi:49 */
		dma2d: dma@4002b000 {
			compatible = "st,stm32-dma2d"; /* in zephyr/dts/arm/st/l4/stm32l496.dtsi:50 */
			reg = < 0x4002b000 0xc00 >;    /* in zephyr/dts/arm/st/l4/stm32l496.dtsi:51 */
			interrupts = < 0x5a 0x0 >;     /* in zephyr/dts/arm/st/l4/stm32l496.dtsi:52 */
			status = "disabled";           /* in zephyr/dts/arm/st/l4/stm32l496.dtsi:53 */
		};
	};

	/* node '/cpus' defined in zephyr/dts/arm/st/l4/stm32l4.dtsi:30 */
	cpus {
		#address-cells = < 0x1 >; /* in zephyr/dts/arm/st/l4/stm32l4.dtsi:31 */
		#size-cells = < 0x0 >;    /* in zephyr/dts/arm/st/l4/stm32l4.dtsi:32 */

		/* node '/cpus/cpu@0' defined in zephyr/dts/arm/st/l4/stm32l4.dtsi:34 */
		cpu0: cpu@0 {
			compatible = "arm,cortex-m4f";               /* in zephyr/dts/arm/st/l4/stm32l4.dtsi:35 */
			reg = < 0x0 >;                               /* in zephyr/dts/arm/st/l4/stm32l4.dtsi:36 */
			device_type = "cpu";                         /* in zephyr/dts/arm/st/l4/stm32l4.dtsi:37 */
			cpu-power-states = < &stop0 &stop1 &stop2 >; /* in zephyr/dts/arm/st/l4/stm32l4.dtsi:38 */
		};

		/* node '/cpus/power-states' defined in zephyr/dts/arm/st/l4/stm32l4.dtsi:41 */
		power-states {

			/* node '/cpus/power-states/state0' defined in zephyr/dts/arm/st/l4/stm32l4.dtsi:42 */
			stop0: state0 {
				compatible = "zephyr,power-state";    /* in zephyr/dts/arm/st/l4/stm32l4.dtsi:43 */
				power-state-name = "suspend-to-idle"; /* in zephyr/dts/arm/st/l4/stm32l4.dtsi:44 */
				substate-id = < 0x1 >;                /* in zephyr/dts/arm/st/l4/stm32l4.dtsi:45 */
				min-residency-us = < 0x1f4 >;         /* in zephyr/dts/arm/st/l4/stm32l4.dtsi:46 */
				phandle = < 0x1b >;                   /* in zephyr/dts/arm/st/l4/stm32l4.dtsi:38 */
			};

			/* node '/cpus/power-states/state1' defined in zephyr/dts/arm/st/l4/stm32l4.dtsi:49 */
			stop1: state1 {
				compatible = "zephyr,power-state";    /* in zephyr/dts/arm/st/l4/stm32l4.dtsi:50 */
				power-state-name = "suspend-to-idle"; /* in zephyr/dts/arm/st/l4/stm32l4.dtsi:51 */
				substate-id = < 0x2 >;                /* in zephyr/dts/arm/st/l4/stm32l4.dtsi:52 */
				min-residency-us = < 0x2bc >;         /* in zephyr/dts/arm/st/l4/stm32l4.dtsi:53 */
				phandle = < 0x1c >;                   /* in zephyr/dts/arm/st/l4/stm32l4.dtsi:38 */
			};

			/* node '/cpus/power-states/state2' defined in zephyr/dts/arm/st/l4/stm32l4.dtsi:56 */
			stop2: state2 {
				compatible = "zephyr,power-state";    /* in zephyr/dts/arm/st/l4/stm32l4.dtsi:57 */
				power-state-name = "suspend-to-idle"; /* in zephyr/dts/arm/st/l4/stm32l4.dtsi:58 */
				substate-id = < 0x3 >;                /* in zephyr/dts/arm/st/l4/stm32l4.dtsi:59 */
				min-residency-us = < 0x3e8 >;         /* in zephyr/dts/arm/st/l4/stm32l4.dtsi:60 */
				phandle = < 0x1d >;                   /* in zephyr/dts/arm/st/l4/stm32l4.dtsi:38 */
			};
		};
	};

	/* node '/clocks' defined in zephyr/dts/arm/st/l4/stm32l4.dtsi:65 */
	clocks {

		/* node '/clocks/clk-hse' defined in zephyr/dts/arm/st/l4/stm32l4.dtsi:66 */
		clk_hse: clk-hse {
			compatible = "st,stm32-hse-clock"; /* in zephyr/dts/arm/st/l4/stm32l4.dtsi:67 */
			#clock-cells = < 0x0 >;            /* in zephyr/dts/arm/st/l4/stm32l4.dtsi:68 */
			status = "disabled";               /* in zephyr/dts/arm/st/l4/stm32l4.dtsi:69 */
		};

		/* node '/clocks/clk-hsi' defined in zephyr/dts/arm/st/l4/stm32l4.dtsi:72 */
		clk_hsi: clk-hsi {
			compatible = "fixed-clock";     /* in zephyr/dts/arm/st/l4/stm32l4.dtsi:73 */
			#clock-cells = < 0x0 >;         /* in zephyr/dts/arm/st/l4/stm32l4.dtsi:74 */
			clock-frequency = < 0xf42400 >; /* in zephyr/dts/arm/st/l4/stm32l4.dtsi:75 */
			status = "okay";                /* in zephyr/boards/st/nucleo_l496zg/nucleo_l496zg.dts:76 */
			phandle = < 0x1e >;             /* in zephyr/boards/st/nucleo_l496zg/nucleo_l496zg.dts:89 */
		};

		/* node '/clocks/clk-msi' defined in zephyr/dts/arm/st/l4/stm32l4.dtsi:79 */
		clk_msi: clk-msi {
			compatible = "st,stm32-msi-clock"; /* in zephyr/dts/arm/st/l4/stm32l4.dtsi:80 */
			#clock-cells = < 0x0 >;            /* in zephyr/dts/arm/st/l4/stm32l4.dtsi:81 */
			msi-range = < 0x6 >;               /* in zephyr/dts/arm/st/l4/stm32l4.dtsi:82 */
			status = "disabled";               /* in zephyr/dts/arm/st/l4/stm32l4.dtsi:83 */
		};

		/* node '/clocks/clk-lse' defined in zephyr/dts/arm/st/l4/stm32l4.dtsi:86 */
		clk_lse: clk-lse {
			compatible = "st,stm32-lse-clock"; /* in zephyr/dts/arm/st/l4/stm32l4.dtsi:87 */
			#clock-cells = < 0x0 >;            /* in zephyr/dts/arm/st/l4/stm32l4.dtsi:88 */
			clock-frequency = < 0x8000 >;      /* in zephyr/dts/arm/st/l4/stm32l4.dtsi:89 */
			driving-capability = < 0x0 >;      /* in zephyr/dts/arm/st/l4/stm32l4.dtsi:90 */
			status = "disabled";               /* in zephyr/dts/arm/st/l4/stm32l4.dtsi:91 */
		};

		/* node '/clocks/clk-lsi' defined in zephyr/dts/arm/st/l4/stm32l4.dtsi:94 */
		clk_lsi: clk-lsi {
			compatible = "fixed-clock";   /* in zephyr/dts/arm/st/l4/stm32l4.dtsi:95 */
			#clock-cells = < 0x0 >;       /* in zephyr/dts/arm/st/l4/stm32l4.dtsi:96 */
			clock-frequency = < 0x7d00 >; /* in zephyr/dts/arm/st/l4/stm32l4.dtsi:97 */
			status = "okay";              /* in zephyr/boards/st/nucleo_l496zg/nucleo_l496zg.dts:72 */
		};

		/* node '/clocks/pll' defined in zephyr/dts/arm/st/l4/stm32l4.dtsi:101 */
		pll: pll {
			compatible = "st,stm32l4-pll-clock"; /* in zephyr/dts/arm/st/l4/stm32l4.dtsi:102 */
			#clock-cells = < 0x0 >;              /* in zephyr/dts/arm/st/l4/stm32l4.dtsi:103 */
			div-m = < 0x1 >;                     /* in zephyr/boards/st/nucleo_l496zg/nucleo_l496zg.dts:84 */
			mul-n = < 0x14 >;                    /* in zephyr/boards/st/nucleo_l496zg/nucleo_l496zg.dts:85 */
			div-p = < 0x7 >;                     /* in zephyr/boards/st/nucleo_l496zg/nucleo_l496zg.dts:86 */
			div-q = < 0x2 >;                     /* in zephyr/boards/st/nucleo_l496zg/nucleo_l496zg.dts:87 */
			div-r = < 0x4 >;                     /* in zephyr/boards/st/nucleo_l496zg/nucleo_l496zg.dts:88 */
			clocks = < &clk_hsi >;               /* in zephyr/boards/st/nucleo_l496zg/nucleo_l496zg.dts:89 */
			status = "okay";                     /* in zephyr/boards/st/nucleo_l496zg/nucleo_l496zg.dts:90 */
			phandle = < 0x14 >;                  /* in zephyr/boards/st/nucleo_l496zg/nucleo_l496zg.dts:94 */
		};

		/* node '/clocks/pllsai1' defined in zephyr/dts/arm/st/l4/stm32l4.dtsi:107 */
		pllsai1: pllsai1 {
			compatible = "st,stm32l4-pll-clock"; /* in zephyr/dts/arm/st/l4/stm32l4.dtsi:108 */
			#clock-cells = < 0x0 >;              /* in zephyr/dts/arm/st/l4/stm32l4.dtsi:109 */
			status = "disabled";                 /* in zephyr/dts/arm/st/l4/stm32l4.dtsi:110 */
		};

		/* node '/clocks/pllsai2' defined in zephyr/dts/arm/st/l4/stm32l471.dtsi:11 */
		pllsai2: pllsai2 {
			compatible = "st,stm32l4-pll-clock"; /* in zephyr/dts/arm/st/l4/stm32l471.dtsi:12 */
			#clock-cells = < 0x0 >;              /* in zephyr/dts/arm/st/l4/stm32l471.dtsi:13 */
			status = "disabled";                 /* in zephyr/dts/arm/st/l4/stm32l471.dtsi:14 */
		};

		/* node '/clocks/clk-hsi48' defined in zephyr/dts/arm/st/l4/stm32l496.dtsi:11 */
		clk_hsi48: clk-hsi48 {
			compatible = "fixed-clock";      /* in zephyr/dts/arm/st/l4/stm32l496.dtsi:12 */
			#clock-cells = < 0x0 >;          /* in zephyr/dts/arm/st/l4/stm32l496.dtsi:13 */
			clock-frequency = < 0x2dc6c00 >; /* in zephyr/dts/arm/st/l4/stm32l496.dtsi:14 */
			status = "okay";                 /* in zephyr/boards/st/nucleo_l496zg/nucleo_l496zg.dts:80 */
		};
	};

	/* node '/mcos' defined in zephyr/dts/arm/st/l4/stm32l4.dtsi:114 */
	mcos {

		/* node '/mcos/mco1' defined in zephyr/dts/arm/st/l4/stm32l4.dtsi:115 */
		mco1: mco1 {
			compatible = "st,stm32-clock-mco"; /* in zephyr/dts/arm/st/l4/stm32l4.dtsi:116 */
			clock-names = "clksel";            /* in zephyr/dts/arm/st/l4/stm32l4.dtsi:117 */
			status = "disabled";               /* in zephyr/dts/arm/st/l4/stm32l4.dtsi:118 */
		};
	};

	/* node '/dietemp' defined in zephyr/dts/arm/st/l4/stm32l4.dtsi:598 */
	die_temp: dietemp {
		compatible = "st,stm32-temp-cal"; /* in zephyr/dts/arm/st/l4/stm32l4.dtsi:599 */
		nvmem-cells = < &ts_cal1_otp >,
		              < &ts_cal2_otp >;   /* in zephyr/dts/arm/st/l4/stm32l4.dtsi:600 */
		nvmem-cell-names = "TS_CAL1",
		                   "TS_CAL2";     /* in zephyr/dts/arm/st/l4/stm32l4.dtsi:601 */
		ts-cal1-temp = < 0x1e >;          /* in zephyr/dts/arm/st/l4/stm32l4.dtsi:602 */
		ts-cal-vrefanalog = < 0xbb8 >;    /* in zephyr/dts/arm/st/l4/stm32l4.dtsi:604 */
		io-channels = < &adc1 0x11 >;     /* in zephyr/dts/arm/st/l4/stm32l4.dtsi:605 */
		status = "disabled";              /* in zephyr/dts/arm/st/l4/stm32l4.dtsi:606 */
		ts-cal2-temp = < 0x82 >;          /* in zephyr/dts/arm/st/l4/stm32l496.dtsi:81 */
	};

	/* node '/vref' defined in zephyr/dts/arm/st/l4/stm32l4.dtsi:609 */
	vref: vref {
		compatible = "st,stm32-vref";   /* in zephyr/dts/arm/st/l4/stm32l4.dtsi:610 */
		nvmem-cells = < &vrefint_otp >; /* in zephyr/dts/arm/st/l4/stm32l4.dtsi:611 */
		vrefint-cal-mv = < 0xbb8 >;     /* in zephyr/dts/arm/st/l4/stm32l4.dtsi:612 */
		io-channels = < &adc1 0x0 >;    /* in zephyr/dts/arm/st/l4/stm32l4.dtsi:613 */
		status = "disabled";            /* in zephyr/dts/arm/st/l4/stm32l4.dtsi:614 */
	};

	/* node '/vbat' defined in zephyr/dts/arm/st/l4/stm32l4.dtsi:617 */
	vbat: vbat {
		compatible = "st,stm32-vbat"; /* in zephyr/dts/arm/st/l4/stm32l4.dtsi:618 */
		ratio = < 0x3 >;              /* in zephyr/dts/arm/st/l4/stm32l4.dtsi:619 */
		io-channels = < &adc1 0x12 >; /* in zephyr/dts/arm/st/l4/stm32l4.dtsi:620 */
		status = "disabled";          /* in zephyr/dts/arm/st/l4/stm32l4.dtsi:621 */
	};

	/* node '/smbus1' defined in zephyr/dts/arm/st/l4/stm32l4.dtsi:624 */
	smbus1: smbus1 {
		compatible = "st,stm32-smbus"; /* in zephyr/dts/arm/st/l4/stm32l4.dtsi:625 */
		#address-cells = < 0x1 >;      /* in zephyr/dts/arm/st/l4/stm32l4.dtsi:626 */
		#size-cells = < 0x0 >;         /* in zephyr/dts/arm/st/l4/stm32l4.dtsi:627 */
		i2c = < &i2c1 >;               /* in zephyr/dts/arm/st/l4/stm32l4.dtsi:628 */
		status = "disabled";           /* in zephyr/dts/arm/st/l4/stm32l4.dtsi:629 */
	};

	/* node '/smbus3' defined in zephyr/dts/arm/st/l4/stm32l4.dtsi:632 */
	smbus3: smbus3 {
		compatible = "st,stm32-smbus"; /* in zephyr/dts/arm/st/l4/stm32l4.dtsi:633 */
		#address-cells = < 0x1 >;      /* in zephyr/dts/arm/st/l4/stm32l4.dtsi:634 */
		#size-cells = < 0x0 >;         /* in zephyr/dts/arm/st/l4/stm32l4.dtsi:635 */
		i2c = < &i2c3 >;               /* in zephyr/dts/arm/st/l4/stm32l4.dtsi:636 */
		status = "disabled";           /* in zephyr/dts/arm/st/l4/stm32l4.dtsi:637 */
	};

	/* node '/memory@20000000' defined in zephyr/dts/arm/st/l4/stm32l4.dtsi:640 */
	sram0: memory@20000000 {
		compatible = "zephyr,memory-region",
		             "mmio-sram";            /* in zephyr/dts/arm/st/l4/stm32l4.dtsi:641 */
		zephyr,memory-region = "SRAM0";      /* in zephyr/dts/arm/st/l4/stm32l4.dtsi:642 */
		reg = < 0x20000000 0x40000 >;        /* in zephyr/dts/arm/st/l4/stm32l496Xg.dtsi:23 */
	};

	/* node '/smbus2' defined in zephyr/dts/arm/st/l4/stm32l471.dtsi:429 */
	smbus2: smbus2 {
		compatible = "st,stm32-smbus"; /* in zephyr/dts/arm/st/l4/stm32l471.dtsi:430 */
		#address-cells = < 0x1 >;      /* in zephyr/dts/arm/st/l4/stm32l471.dtsi:431 */
		#size-cells = < 0x0 >;         /* in zephyr/dts/arm/st/l4/stm32l471.dtsi:432 */
		i2c = < &i2c2 >;               /* in zephyr/dts/arm/st/l4/stm32l471.dtsi:433 */
		status = "disabled";           /* in zephyr/dts/arm/st/l4/stm32l471.dtsi:434 */
	};

	/* node '/memory@10000000' defined in zephyr/dts/arm/st/l4/stm32l471.dtsi:437 */
	sram1: memory@10000000 {
		compatible = "zephyr,memory-region",
		             "mmio-sram";            /* in zephyr/dts/arm/st/l4/stm32l471.dtsi:438 */
		zephyr,memory-region = "SRAM1";      /* in zephyr/dts/arm/st/l4/stm32l471.dtsi:439 */
		reg = < 0x10000000 0x10000 >;        /* in zephyr/dts/arm/st/l4/stm32l496Xg.dtsi:19 */
	};

	/* node '/otgfs_phy' defined in zephyr/dts/arm/st/l4/stm32l475.dtsi:28 */
	otgfs_phy: otgfs_phy {
		compatible = "usb-nop-xceiv"; /* in zephyr/dts/arm/st/l4/stm32l475.dtsi:29 */
		#phy-cells = < 0x0 >;         /* in zephyr/dts/arm/st/l4/stm32l475.dtsi:30 */
		phandle = < 0x18 >;           /* in zephyr/dts/arm/st/l4/stm32l475.dtsi:21 */
	};

	/* node '/smbus4' defined in zephyr/dts/arm/st/l4/stm32l496.dtsi:84 */
	smbus4: smbus4 {
		compatible = "st,stm32-smbus"; /* in zephyr/dts/arm/st/l4/stm32l496.dtsi:85 */
		#address-cells = < 0x1 >;      /* in zephyr/dts/arm/st/l4/stm32l496.dtsi:86 */
		#size-cells = < 0x0 >;         /* in zephyr/dts/arm/st/l4/stm32l496.dtsi:87 */
		i2c = < &i2c4 >;               /* in zephyr/dts/arm/st/l4/stm32l496.dtsi:88 */
		status = "disabled";           /* in zephyr/dts/arm/st/l4/stm32l496.dtsi:89 */
	};

	/* node '/connector' defined in zephyr/boards/st/nucleo_l496zg/arduino_r3_connector.dtsi:10 */
	arduino_header: connector {
		compatible = "arduino-header-r3";          /* in zephyr/boards/st/nucleo_l496zg/arduino_r3_connector.dtsi:11 */
		#gpio-cells = < 0x2 >;                     /* in zephyr/boards/st/nucleo_l496zg/arduino_r3_connector.dtsi:12 */
		gpio-map-mask = < 0xffffffff 0xffffffc0 >; /* in zephyr/boards/st/nucleo_l496zg/arduino_r3_connector.dtsi:13 */
		gpio-map-pass-thru = < 0x0 0x3f >;         /* in zephyr/boards/st/nucleo_l496zg/arduino_r3_connector.dtsi:14 */
		gpio-map = < 0x0 0x0 &gpioa 0x3 0x0 >,
		           < 0x1 0x0 &gpioc 0x0 0x0 >,
		           < 0x2 0x0 &gpioc 0x3 0x0 >,
		           < 0x3 0x0 &gpioc 0x1 0x0 >,
		           < 0x4 0x0 &gpioc 0x4 0x0 >,
		           < 0x5 0x0 &gpioc 0x5 0x0 >,
		           < 0x6 0x0 &gpiod 0x9 0x0 >,
		           < 0x7 0x0 &gpiod 0x8 0x0 >,
		           < 0x8 0x0 &gpiof 0xf 0x0 >,
		           < 0x9 0x0 &gpioe 0xd 0x0 >,
		           < 0xa 0x0 &gpiof 0xe 0x0 >,
		           < 0xb 0x0 &gpioe 0xb 0x0 >,
		           < 0xc 0x0 &gpioe 0x9 0x0 >,
		           < 0xd 0x0 &gpiof 0xd 0x0 >,
		           < 0xe 0x0 &gpiof 0xc 0x0 >,
		           < 0xf 0x0 &gpiod 0xf 0x0 >,
		           < 0x10 0x0 &gpiod 0xe 0x0 >,
		           < 0x11 0x0 &gpioa 0x7 0x0 >,
		           < 0x12 0x0 &gpioa 0x6 0x0 >,
		           < 0x13 0x0 &gpioa 0x5 0x0 >,
		           < 0x14 0x0 &gpiob 0x9 0x0 >,
		           < 0x15 0x0 &gpiob 0x8 0x0 >;    /* in zephyr/boards/st/nucleo_l496zg/arduino_r3_connector.dtsi:15 */
	};

	/* node '/leds' defined in zephyr/boards/st/nucleo_l496zg/nucleo_l496zg.dts:24 */
	leds: leds {
		compatible = "gpio-leds"; /* in zephyr/boards/st/nucleo_l496zg/nucleo_l496zg.dts:25 */

		/* node '/leds/led_1' defined in zephyr/boards/st/nucleo_l496zg/nucleo_l496zg.dts:27 */
		green_led_1: led_1 {
			gpios = < &gpioc 0x7 0x0 >; /* in zephyr/boards/st/nucleo_l496zg/nucleo_l496zg.dts:28 */
			label = "User LD1";         /* in zephyr/boards/st/nucleo_l496zg/nucleo_l496zg.dts:29 */
		};

		/* node '/leds/led_2' defined in zephyr/boards/st/nucleo_l496zg/nucleo_l496zg.dts:32 */
		blue_led_2: led_2 {
			gpios = < &gpiob 0x7 0x0 >; /* in zephyr/boards/st/nucleo_l496zg/nucleo_l496zg.dts:33 */
			label = "User LD2";         /* in zephyr/boards/st/nucleo_l496zg/nucleo_l496zg.dts:34 */
		};

		/* node '/leds/led_3' defined in zephyr/boards/st/nucleo_l496zg/nucleo_l496zg.dts:37 */
		red_led_3: led_3 {
			gpios = < &gpiob 0xe 0x0 >; /* in zephyr/boards/st/nucleo_l496zg/nucleo_l496zg.dts:38 */
			label = "User LD3";         /* in zephyr/boards/st/nucleo_l496zg/nucleo_l496zg.dts:39 */
		};

		/* node '/leds/hotfire_led' defined in ../projects/grp/daq-module/firmware/app.overlay:6 */
		hotfire_led: hotfire_led {
			gpios = < &gpiob 0x1 0x0 >;   /* in ../projects/grp/daq-module/firmware/app.overlay:7 */
			label = "Hotfire LED5 (PB1)"; /* in ../projects/grp/daq-module/firmware/app.overlay:8 */
		};
	};

	/* node '/pwmleds' defined in zephyr/boards/st/nucleo_l496zg/nucleo_l496zg.dts:43 */
	pwmleds {
		compatible = "pwm-leds"; /* in zephyr/boards/st/nucleo_l496zg/nucleo_l496zg.dts:44 */

		/* node '/pwmleds/red_pwm_led' defined in zephyr/boards/st/nucleo_l496zg/nucleo_l496zg.dts:46 */
		red_pwm_led: red_pwm_led {
			pwms = < &pwm15 0x1 0x1312d00 0x0 >; /* in zephyr/boards/st/nucleo_l496zg/nucleo_l496zg.dts:47 */
		};
	};

	/* node '/gpio_keys' defined in zephyr/boards/st/nucleo_l496zg/nucleo_l496zg.dts:51 */
	gpio_keys {
		compatible = "gpio-keys"; /* in zephyr/boards/st/nucleo_l496zg/nucleo_l496zg.dts:52 */

		/* node '/gpio_keys/button' defined in zephyr/boards/st/nucleo_l496zg/nucleo_l496zg.dts:54 */
		user_button: button {
			label = "User Button";      /* in zephyr/boards/st/nucleo_l496zg/nucleo_l496zg.dts:55 */
			gpios = < &gpioc 0xd 0x0 >; /* in zephyr/boards/st/nucleo_l496zg/nucleo_l496zg.dts:56 */
			zephyr,code = < 0xb >;      /* in zephyr/boards/st/nucleo_l496zg/nucleo_l496zg.dts:57 */
		};
	};
};
